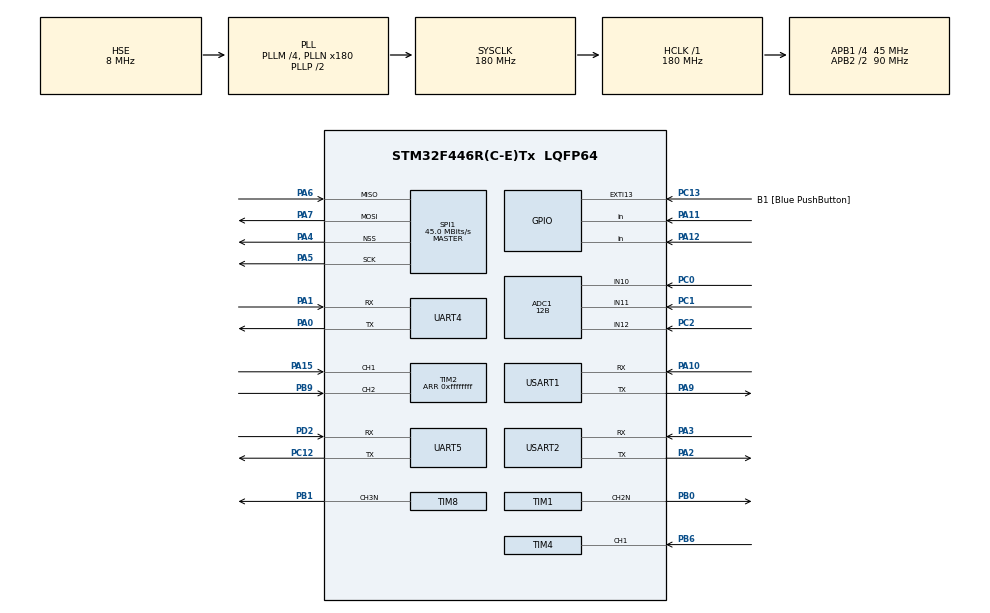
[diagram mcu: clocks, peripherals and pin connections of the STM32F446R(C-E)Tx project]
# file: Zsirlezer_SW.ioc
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ADC1.Channel-0\#ChannelRegularConversion=ADC_CHANNEL_10
ADC1.Channel-1\#ChannelRegularConversion=ADC_CHANNEL_11
ADC1.Channel-2\#ChannelRegularConversion=ADC_CHANNEL_12
ADC1.ClockPrescaler=ADC_CLOCK_SYNC_PCLK_DIV4
ADC1.ContinuousConvMode=DISABLE
ADC1.DMAContinuousRequests=ENABLE
ADC1.DataAlign=ADC_DATAALIGN_RIGHT
ADC1.DiscontinuousConvMode=DISABLE
ADC1.EOCSelection=ADC_EOC_SINGLE_CONV
ADC1.EnableAnalogWatchDog=false
ADC1.ExternalTrigConvEdge=ADC_EXTERNALTRIGCONVEDGE_NONE
ADC1.InjNumberOfConversion=0
ADC1.NbrOfConversion=3
ADC1.NbrOfConversionFlag=1
ADC1.Rank-0\#ChannelRegularConversion=1
ADC1.Rank-1\#ChannelRegularConversion=2
ADC1.Rank-2\#ChannelRegularConversion=3
ADC1.Resolution=ADC_RESOLUTION_12B
ADC1.SamplingTime-0\#ChannelRegularConversion=ADC_SAMPLETIME_15CYCLES
ADC1.SamplingTime-1\#ChannelRegularConversion=ADC_SAMPLETIME_15CYCLES
ADC1.SamplingTime-2\#ChannelRegularConversion=ADC_SAMPLETIME_15CYCLES
ADC1.ScanConvMode=ENABLE
ADC1.master=1
Dma.ADC1.0.Direction=DMA_PERIPH_TO_MEMORY
Dma.ADC1.0.FIFOMode=DMA_FIFOMODE_DISABLE
Dma.ADC1.0.Instance=DMA2_Stream0
Dma.ADC1.0.MemDataAlignment=DMA_MDATAALIGN_HALFWORD
Dma.ADC1.0.MemInc=DMA_MINC_ENABLE
Dma.ADC1.0.Mode=DMA_CIRCULAR
Dma.ADC1.0.PeriphDataAlignment=DMA_PDATAALIGN_HALFWORD
Dma.ADC1.0.PeriphInc=DMA_PINC_DISABLE
Dma.ADC1.0.Priority=DMA_PRIORITY_LOW
Dma.Request0=ADC1
Dma.Request1=USART1_RX
Dma.Request2=USART1_TX
Dma.USART1_RX.1.Direction=DMA_PERIPH_TO_MEMORY
Dma.USART1_RX.1.FIFOMode=DMA_FIFOMODE_DISABLE
Dma.USART1_RX.1.Instance=DMA2_Stream2
Dma.USART1_RX.1.MemDataAlignment=DMA_MDATAALIGN_BYTE
Dma.USART1_RX.1.MemInc=DMA_MINC_ENABLE
Dma.USART1_RX.1.Mode=DMA_CIRCULAR
Dma.USART1_RX.1.PeriphDataAlignment=DMA_PDATAALIGN_BYTE
Dma.USART1_RX.1.PeriphInc=DMA_PINC_DISABLE
Dma.USART1_RX.1.Priority=DMA_PRIORITY_HIGH
Dma.USART1_TX.2.Direction=DMA_MEMORY_TO_PERIPH
Dma.USART1_TX.2.FIFOMode=DMA_FIFOMODE_DISABLE
Dma.USART1_TX.2.Instance=DMA2_Stream7
Dma.USART1_TX.2.MemDataAlignment=DMA_MDATAALIGN_BYTE
Dma.USART1_TX.2.MemInc=DMA_MINC_ENABLE
Dma.USART1_TX.2.Mode=DMA_NORMAL
Dma.USART1_TX.2.PeriphDataAlignment=DMA_PDATAALIGN_BYTE
Dma.USART1_TX.2.PeriphInc=DMA_PINC_DISABLE
Dma.USART1_TX.2.Priority=DMA_PRIORITY_MEDIUM
Mcu.Family=STM32F4
Mcu.Name=STM32F446R(C-E)Tx
Mcu.Package=LQFP64
NVIC.DMA2_Stream0_IRQn=true\:0\:0\:false\:false\:true
NVIC.DMA2_Stream2_IRQn=true\:0\:0\:false\:false\:true
NVIC.DMA2_Stream7_IRQn=true\:0\:0\:false\:false\:true
NVIC.PriorityGroup=NVIC_PRIORITYGROUP_0
NVIC.TIM4_IRQn=true\:0\:2\:true\:false\:true
NVIC.TIM6_DAC_IRQn=true\:0\:2\:false\:false\:true
NVIC.TIM7_IRQn=true\:0\:2\:false\:false\:true
NVIC.UART4_IRQn=true\:0\:0\:false\:false\:true
NVIC.USART1_IRQn=true\:0\:0\:true\:false\:true
NVIC.USART2_IRQn=true\:0\:0\:false\:false\:true
PA0-WKUP.Mode=Asynchronous
PA0-WKUP.Signal=UART4_TX
PA1.Mode=Asynchronous
PA1.Signal=UART4_RX
PA10.Mode=Asynchronous
PA10.Signal=USART1_RX
PA11.Signal=GPIO_Input
PA12.Signal=GPIO_Input
PA13.GPIO_Label=TMS
PA13.Signal=SYS_JTMS-SWDIO
PA14.GPIO_Label=TCK
PA14.Signal=SYS_JTCK-SWCLK
PA15.Signal=S_TIM2_CH1_ETR
PA2.Mode=Asynchronous
PA2.Signal=USART2_TX
PA3.Mode=Asynchronous
PA3.Signal=USART2_RX
PA4.Mode=NSS_Signal_Hard_Output
PA4.Signal=SPI1_NSS
PA5.Mode=Full_Duplex_Master
PA5.Signal=SPI1_SCK
PA6.Mode=Full_Duplex_Master
PA6.Signal=SPI1_MISO
PA7.Mode=Full_Duplex_Master
PA7.Signal=SPI1_MOSI
PA9.Mode=Asynchronous
PA9.Signal=USART1_TX
PB0.GPIO_ModeDefaultPP=GPIO_MODE_AF_PP
PB0.Mode=PWM Generation2 CH2N
PB0.Signal=TIM1_CH2N
PB1.Mode=PWM Generation3 CH3N
PB1.Signal=TIM8_CH3N
PB3.GPIO_Label=SWO
PB3.Signal=SYS_JTDO-SWO
PB6.Signal=S_TIM4_CH1
PB9.Signal=S_TIM2_CH2
PC0.Signal=ADCx_IN10
PC1.Signal=ADCx_IN11
PC12.Mode=Asynchronous
PC12.Signal=UART5_TX
PC13.GPIO_Label=B1 [Blue PushButton]
PC13.GPIO_ModeDefaultEXTI=GPIO_MODE_EVT_RISING
PC13.Signal=GPXTI13
PC2.Signal=ADCx_IN12
PD2.Mode=Asynchronous
PD2.Signal=UART5_RX
PH0-OSC_IN.Mode=HSE-External-Oscillator
PH0-OSC_IN.Signal=RCC_OSC_IN
PH1-OSC_OUT.Mode=HSE-External-Oscillator
PH1-OSC_OUT.Signal=RCC_OSC_OUT
ProjectManager.HeapSize=0x200
ProjectManager.StackSize=0x400
ProjectManager.TargetToolchain=SW4STM32
RCC.AHBFreq_Value=180000000
RCC.APB1CLKDivider=RCC_HCLK_DIV4
RCC.APB1Freq_Value=45000000
RCC.APB1TimFreq_Value=90000000
RCC.APB2CLKDivider=RCC_HCLK_DIV2
RCC.APB2Freq_Value=90000000
RCC.APB2TimFreq_Value=180000000
RCC.CortexFreq_Value=180000000
RCC.FLatency-AdvancedSettings=FLASH_LATENCY_5
RCC.HCLKFreq_Value=180000000
RCC.HSE_VALUE=8000000
RCC.HSI_VALUE=16000000
RCC.LSE_VALUE=32768
RCC.PLLM=4
RCC.PLLN=180
RCC.PLLSourceVirtual=RCC_PLLSOURCE_HSE
RCC.SYSCLKFreq_VALUE=180000000
RCC.SYSCLKSource=RCC_SYSCLKSOURCE_PLLCLK
RCC.USBFreq_Value=180000000
RCC.VCOOutputFreq_Value=360000000
SH.ADCx_IN10.0=ADC1_IN10,IN10
SH.ADCx_IN11.0=ADC1_IN11,IN11
SH.ADCx_IN12.0=ADC1_IN12,IN12
SH.S_TIM2_CH1_ETR.0=TIM2_CH1,Encoder_Interface
SH.S_TIM2_CH2.0=TIM2_CH2,Encoder_Interface
SH.S_TIM4_CH1.0=TIM4_CH1,Input_Capture1_from_TI1
SPI1.CalculateBaudRate=45.0 MBits/s
SPI1.Mode=SPI_MODE_MASTER
SPI1.VirtualNSS=VM_NSSHARD
TIM1.Channel-PWM\ Generation2\ CH2N=TIM_CHANNEL_2
TIM1.Period=64614
TIM1.Prescaler=38
TIM1.Pulse-PWM\ Generation2\ CH2N=7497
TIM2.Period=0xffffffff
TIM4.ICPolarity_CH1=TIM_INPUTCHANNELPOLARITY_BOTHEDGE
TIM4.Period=64614
TIM4.Prescaler=38
TIM6.Period=65454
TIM6.Prescaler=65
TIM7.Period=9999
TIM7.Prescaler=89
TIM8.Channel-PWM\ Generation3\ CH3N=TIM_CHANNEL_3
TIM8.Period=64614
TIM8.Prescaler=38
TIM8.Pulse-PWM\ Generation3\ CH3N=6932
VP_TIM6_VS_ClockSourceINT.Mode=Enable_Timer
VP_TIM7_VS_ClockSourceINT.Mode=Enable_Timer
board=NUCLEO-F446RE

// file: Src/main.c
/**
  ******************************************************************************
  * File Name          : main.c
  * Description        : Main program body
  ******************************************************************************
  *
  * COPYRIGHT(c) 2017 STMicroelectronics
  *
  * Redistribution and use in source and binary forms, with or without modification,
  * are permitted provided that the following conditions are met:
  *   1. Redistributions of source code must retain the above copyright notice,
  *      this list of conditions and the following disclaimer.
  *   2. Redistributions in binary form must reproduce the above copyright notice,
  *      this list of conditions and the following disclaimer in the documentation
  *      and/or other materials provided with the distribution.
  *   3. Neither the name of STMicroelectronics nor the names of its contributors
  *      may be used to endorse or promote products derived from this software
  *      without specific prior written permission.
  *
  * THIS SOFTWARE IS PROVIDED BY THE COPYRIGHT HOLDERS AND CONTRIBUTORS "AS IS"
  * AND ANY EXPRESS OR IMPLIED WARRANTIES, INCLUDING, BUT NOT LIMITED TO, THE
  * IMPLIED WARRANTIES OF MERCHANTABILITY AND FITNESS FOR A PARTICULAR PURPOSE ARE
  * DISCLAIMED. IN NO EVENT SHALL THE COPYRIGHT HOLDER OR CONTRIBUTORS BE LIABLE
  * FOR ANY DIRECT, INDIRECT, INCIDENTAL, SPECIAL, EXEMPLARY, OR CONSEQUENTIAL
  * DAMAGES (INCLUDING, BUT NOT LIMITED TO, PROCUREMENT OF SUBSTITUTE GOODS OR
  * SERVICES; LOSS OF USE, DATA, OR PROFITS; OR BUSINESS INTERRUPTION) HOWEVER
  * CAUSED AND ON ANY THEORY OF LIABILITY, WHETHER IN CONTRACT, STRICT LIABILITY,
  * OR TORT (INCLUDING NEGLIGENCE OR OTHERWISE) ARISING IN ANY WAY OUT OF THE USE
  * OF THIS SOFTWARE, EVEN IF ADVISED OF THE POSSIBILITY OF SUCH DAMAGE.
  *
  ******************************************************************************
  */
#include "main.h"
#include "stm32f4xx_hal.h"
#include "adc.h"
#include "dma.h"
#include "spi.h"
#include "tim.h"
#include "usart.h"
#include "gpio.h"

/* USER CODE BEGIN Includes */
#include "stdbool.h"

//Defineok
//Vonalszam
#define NINCSVONAL 10
#define EGYVONAL 1
#define KETVONAL 2
#define HAROMVONAL 3
#define VONALHIBA 15
#define FULLVONAL 70

//UTVONANALVALASZTAS
#define JOBB 30
#define BAL 45
#define NORMAL_VONALKOVETES 50
#define MINDKET_OLDAL 60

//Vonalobjektumok
#define GYORSITO 5
#define LASSITO 6

#define DRONE 7
#define GYALOGOS 8
#define HORDO 9
#define KORFORGO 11
#define CEL 12
#define SIMA_VEZETOVONAL 13
#define STARTRA_VAR 22
#define LIBIKOKA_JOBBRA 16
#define LIBIKOKA_BALRA 17
#define TELEPHELY_JOBBRA 18
#define TELEPHELY_BALRA 19
#define PARKOLO_BALRA 20
#define PARKOLO_JOBBRA 21

/* USER CODE END Includes */

/* USER CODE BEGIN PV */
/* Private variables ---------------------------------------------------------*/

float atan_lut[5400] = {
	 2320.5616,
	 2320.0878, 2319.6137, 2319.1394, 2318.6649, 2318.1902, 2317.7153, 2317.2401, 2316.7648, 2316.2892, 2315.8135,
	 2315.3375, 2314.8613, 2314.3849, 2313.9083, 2313.4314, 2312.9544, 2312.4771, 2311.9997, 2311.522, 2311.0441,
	 2310.566, 2310.0876, 2309.6091, 2309.1303, 2308.6514, 2308.1722, 2307.6928, 2307.2132, 2306.7334, 2306.2533,
	 2305.7731, 2305.2926, 2304.8119, 2304.331, 2303.8499, 2303.3686, 2302.8871, 2302.4053, 2301.9233, 2301.4411,
	 2300.9587, 2300.4761, 2299.9933, 2299.5102, 2299.027, 2298.5435, 2298.0598, 2297.5759, 2297.0917, 2296.6074,
	 2296.1228, 2295.638, 2295.153, 2294.6678, 2294.1824, 2293.6967, 2293.2109, 2292.7248, 2292.2385, 2291.7519,
	 2291.2652, 2290.7782, 2290.2911, 2289.8037, 2289.3161, 2288.8282, 2288.3402, 2287.8519, 2287.3634, 2286.8747,
	 2286.3858, 2285.8967, 2285.4073, 2284.9177, 2284.4279, 2283.9379, 2283.4476, 2282.9572, 2282.4665, 2281.9756,
	 2281.4845, 2280.9931, 2280.5016, 2280.0098, 2279.5178, 2279.0256, 2278.5331, 2278.0404, 2277.5476, 2277.0544,
	 2276.5611, 2276.0676, 2275.5738, 2275.0798, 2274.5856, 2274.0911, 2273.5965, 2273.1016, 2272.6065, 2272.1112,
	 2271.6156, 2271.1199, 2270.6239, 2270.1276, 2269.6312, 2269.1345, 2268.6377, 2268.1405, 2267.6432, 2267.1457,
	 2266.6479, 2266.1499, 2265.6517, 2265.1532, 2264.6545, 2264.1556, 2263.6565, 2263.1572, 2262.6576, 2262.1578,
	 2261.6578, 2261.1575, 2260.657, 2260.1563, 2259.6554, 2259.1543, 2258.6529, 2258.1513, 2257.6495, 2257.1474,
	 2256.6452, 2256.1427, 2255.6399, 2255.137, 2254.6338, 2254.1304, 2253.6268, 2253.1229, 2252.6188, 2252.1145,
	 2251.61, 2251.1052, 2250.6002, 2250.095, 2249.5895, 2249.0839, 2248.5779, 2248.0718, 2247.5655, 2247.0589,
	 2246.552, 2246.045, 2245.5377, 2245.0302, 2244.5225, 2244.0145, 2243.5063, 2242.9979, 2242.4893, 2241.9804,
	 2241.4713, 2240.962, 2240.4524, 2239.9426, 2239.4326, 2238.9223, 2238.4118, 2237.9011, 2237.3902, 2236.879,
	 2236.3676, 2235.856, 2235.3441, 2234.832, 2234.3197, 2233.8071, 2233.2943, 2232.7813, 2232.2681, 2231.7546,
	 2231.2409, 2230.7269, 2230.2127, 2229.6983, 2229.1837, 2228.6688, 2228.1537, 2227.6383, 2227.1228, 2226.607,
	 2226.0909, 2225.5746, 2225.0581, 2224.5414, 2224.0244, 2223.5072, 2222.9898, 2222.4721, 2221.9542, 2221.4361,
	 2220.9177, 2220.3991, 2219.8802, 2219.3612, 2218.8418, 2218.3223, 2217.8025, 2217.2825, 2216.7622, 2216.2418,
	 2215.721, 2215.2001, 2214.6789, 2214.1575, 2213.6358, 2213.1139, 2212.5918, 2212.0694, 2211.5468, 2211.0239,
	 2210.5009, 2209.9775, 2209.454, 2208.9302, 2208.4062, 2207.8819, 2207.3574, 2206.8327, 2206.3077, 2205.7825,
	 2205.257, 2204.7313, 2204.2054, 2203.6792, 2203.1528, 2202.6262, 2202.0993, 2201.5722, 2201.0448, 2200.5172,
	 2199.9894, 2199.4613, 2198.933, 2198.4045, 2197.8757, 2197.3467, 2196.8174, 2196.2879, 2195.7581, 2195.2281,
	 2194.6979, 2194.1675, 2193.6367, 2193.1058, 2192.5746, 2192.0432, 2191.5115, 2190.9796, 2190.4474, 2189.9151,
	 2189.3824, 2188.8495, 2188.3164, 2187.7831, 2187.2495, 2186.7156, 2186.1815, 2185.6472, 2185.1126, 2184.5778,
	 2184.0428, 2183.5075, 2182.972, 2182.4362, 2181.9002, 2181.3639, 2180.8274, 2180.2906, 2179.7536, 2179.2164,
	 2178.6789, 2178.1412, 2177.6032, 2177.065, 2176.5265, 2175.9878, 2175.4489, 2174.9097, 2174.3703, 2173.8306,
	 2173.2907, 2172.7505, 2172.2101, 2171.6694, 2171.1285, 2170.5874, 2170.046, 2169.5043, 2168.9624, 2168.4203,
	 2167.8779, 2167.3353, 2166.7924, 2166.2493, 2165.706, 2165.1623, 2164.6185, 2164.0744, 2163.53, 2162.9854,
	 2162.4406, 2161.8955, 2161.3502, 2160.8046, 2160.2587, 2159.7127, 2159.1663, 2158.6197, 2158.0729, 2157.5258,
	 2156.9785, 2156.4309, 2155.8831, 2155.3351, 2154.7867, 2154.2382, 2153.6894, 2153.1403, 2152.591, 2152.0414,
	 2151.4916, 2150.9415, 2150.3912, 2149.8407, 2149.2898, 2148.7388, 2148.1875, 2147.6359, 2147.0841, 2146.532,
	 2145.9797, 2145.4271, 2144.8743, 2144.3212, 2143.7679, 2143.2144, 2142.6605, 2142.1065, 2141.5521, 2140.9976,
	 2140.4427, 2139.8876, 2139.3323, 2138.7767, 2138.2209, 2137.6648, 2137.1084, 2136.5518, 2135.995, 2135.4379,
	 2134.8805, 2134.3229, 2133.765, 2133.2069, 2132.6486, 2132.0899, 2131.531, 2130.9719, 2130.4125, 2129.8529,
	 2129.293, 2128.7328, 2128.1724, 2127.6118, 2127.0508, 2126.4897, 2125.9282, 2125.3666, 2124.8046, 2124.2424,
	 2123.68, 2123.1173, 2122.5543, 2121.9911, 2121.4276, 2120.8639, 2120.2999, 2119.7357, 2119.1712, 2118.6064,
	 2118.0414, 2117.4761, 2116.9106, 2116.3448, 2115.7788, 2115.2125, 2114.6459, 2114.0791, 2113.512, 2112.9447,
	 2112.3771, 2111.8093, 2111.2412, 2110.6728, 2110.1042, 2109.5353, 2108.9662, 2108.3968, 2107.8271, 2107.2572,
	 2106.687, 2106.1166, 2105.5459, 2104.9749, 2104.4037, 2103.8322, 2103.2605, 2102.6885, 2102.1163, 2101.5437,
	 2100.971, 2100.3979, 2099.8246, 2099.2511, 2098.6773, 2098.1032, 2097.5288, 2096.9542, 2096.3794, 2095.8042,
	 2095.2288, 2094.6532, 2094.0773, 2093.5011, 2092.9247, 2092.348, 2091.771, 2091.1938, 2090.6163, 2090.0385,
	 2089.4605, 2088.8822, 2088.3037, 2087.7249, 2087.1458, 2086.5665, 2085.9869, 2085.407, 2084.8269, 2084.2465,
	 2083.6659, 2083.085, 2082.5038, 2081.9223, 2081.3406, 2080.7587, 2080.1764, 2079.5939, 2079.0111, 2078.4281,
	 2077.8448, 2077.2612, 2076.6774, 2076.0933, 2075.5089, 2074.9243, 2074.3394, 2073.7543, 2073.1688, 2072.5831,
	 2071.9972, 2071.4109, 2070.8244, 2070.2377, 2069.6506, 2069.0633, 2068.4758, 2067.8879, 2067.2998, 2066.7115,
	 2066.1228, 2065.5339, 2064.9448, 2064.3553, 2063.7656, 2063.1756, 2062.5854, 2061.9949, 2061.4041, 2060.813,
	 2060.2217, 2059.6301, 2059.0382, 2058.4461, 2057.8537, 2057.261, 2056.6681, 2056.0749, 2055.4814, 2054.8876,
	 2054.2936, 2053.6993, 2053.1048, 2052.5099, 2051.9148, 2051.3194, 2050.7238, 2050.1279, 2049.5317, 2048.9352,
	 2048.3385, 2047.7415, 2047.1442, 2046.5467, 2045.9488, 2045.3507, 2044.7524, 2044.1537, 2043.5548, 2042.9556,
	 2042.3562, 2041.7564, 2041.1564, 2040.5562, 2039.9556, 2039.3548, 2038.7537, 2038.1523, 2037.5507, 2036.9488,
	 2036.3466, 2035.7441, 2035.1414, 2034.5383, 2033.935, 2033.3315, 2032.7276, 2032.1235, 2031.5191, 2030.9145,
	 2030.3095, 2029.7043, 2029.0988, 2028.493, 2027.887, 2027.2807, 2026.6741, 2026.0672, 2025.4601, 2024.8526,
	 2024.2449, 2023.6369, 2023.0287, 2022.4202, 2021.8113, 2021.2023, 2020.5929, 2019.9833, 2019.3733, 2018.7631,
	 2018.1527, 2017.5419, 2016.9309, 2016.3196, 2015.708, 2015.0961, 2014.484, 2013.8715, 2013.2588, 2012.6459,
	 2012.0326, 2011.4191, 2010.8052, 2010.1911, 2009.5768, 2008.9621, 2008.3472, 2007.7319, 2007.1165, 2006.5007,
	 2005.8846, 2005.2683, 2004.6517, 2004.0348, 2003.4176, 2002.8001, 2002.1824, 2001.5643, 2000.946, 2000.3275,
	 1999.7086, 1999.0894, 1998.47, 1997.8503, 1997.2303, 1996.61, 1995.9895, 1995.3686, 1994.7475, 1994.1261,
	 1993.5044, 1992.8824, 1992.2602, 1991.6376, 1991.0148, 1990.3917, 1989.7683, 1989.1446, 1988.5207, 1987.8964,
	 1987.2719, 1986.6471, 1986.022, 1985.3966, 1984.771, 1984.145, 1983.5188, 1982.8923, 1982.2655, 1981.6384,
	 1981.011, 1980.3834, 1979.7554, 1979.1272, 1978.4987, 1977.8699, 1977.2408, 1976.6114, 1975.9818, 1975.3518,
	 1974.7216, 1974.0911, 1973.4603, 1972.8292, 1972.1978, 1971.5661, 1970.9342, 1970.302, 1969.6694, 1969.0366,
	 1968.4035, 1967.7701, 1967.1364, 1966.5025, 1965.8682, 1965.2337, 1964.5989, 1963.9637, 1963.3283, 1962.6926,
	 1962.0567, 1961.4204, 1960.7838, 1960.147, 1959.5098, 1958.8724, 1958.2347, 1957.5967, 1956.9584, 1956.3198,
	 1955.6809, 1955.0417, 1954.4023, 1953.7625, 1953.1225, 1952.4821, 1951.8415, 1951.2006, 1950.5594, 1949.9179,
	 1949.2761, 1948.634, 1947.9917, 1947.349, 1946.706, 1946.0628, 1945.4193, 1944.7754, 1944.1313, 1943.4869,
	 1942.8422, 1942.1972, 1941.5519, 1940.9063, 1940.2604, 1939.6143, 1938.9678, 1938.321, 1937.674, 1937.0266,
	 1936.379, 1935.7311, 1935.0828, 1934.4343, 1933.7855, 1933.1364, 1932.487, 1931.8373, 1931.1873, 1930.537,
	 1929.8864, 1929.2356, 1928.5844, 1927.9329, 1927.2812, 1926.6291, 1925.9767, 1925.3241, 1924.6712, 1924.0179,
	 1923.3644, 1922.7105, 1922.0564, 1921.402, 1920.7473, 1920.0922, 1919.4369, 1918.7813, 1918.1254, 1917.4692,
	 1916.8127, 1916.1559, 1915.4988, 1914.8414, 1914.1837, 1913.5257, 1912.8674, 1912.2088, 1911.5499, 1910.8907,
	 1910.2312, 1909.5715, 1908.9114, 1908.251, 1907.5903, 1906.9293, 1906.2681, 1905.6065, 1904.9446, 1904.2824,
	 1903.6199, 1902.9572, 1902.2941, 1901.6307, 1900.967, 1900.3031, 1899.6388, 1898.9742, 1898.3093, 1897.6442,
	 1896.9787, 1896.3129, 1895.6468, 1894.9804, 1894.3137, 1893.6468, 1892.9795, 1892.3119, 1891.644, 1890.9758,
	 1890.3073, 1889.6385, 1888.9694, 1888.3, 1887.6303, 1886.9603, 1886.29, 1885.6194, 1884.9485, 1884.2772,
	 1883.6057, 1882.9339, 1882.2618, 1881.5893, 1880.9166, 1880.2435, 1879.5702, 1878.8966, 1878.2226, 1877.5483,
	 1876.8738, 1876.1989, 1875.5238, 1874.8483, 1874.1725, 1873.4964, 1872.82, 1872.1433, 1871.4663, 1870.789,
	 1870.1114, 1869.4335, 1868.7553, 1868.0768, 1867.3979, 1866.7188, 1866.0393, 1865.3596, 1864.6795, 1863.9992,
	 1863.3185, 1862.6375, 1861.9562, 1861.2746, 1860.5927, 1859.9105, 1859.228, 1858.5452, 1857.8621, 1857.1786,
	 1856.4949, 1855.8108, 1855.1265, 1854.4418, 1853.7568, 1853.0715, 1852.3859, 1851.7, 1851.0138, 1850.3273,
	 1849.6405, 1848.9533, 1848.2659, 1847.5781, 1846.8901, 1846.2017, 1845.513, 1844.824, 1844.1347, 1843.4451,
	 1842.7551, 1842.0649, 1841.3744, 1840.6835, 1839.9923, 1839.3009, 1838.6091, 1837.917, 1837.2246, 1836.5318,
	 1835.8388, 1835.1455, 1834.4518, 1833.7578, 1833.0636, 1832.369, 1831.6741, 1830.9789, 1830.2833, 1829.5875,
	 1828.8913, 1828.1949, 1827.4981, 1826.801, 1826.1036, 1825.4059, 1824.7079, 1824.0095, 1823.3109, 1822.6119,
	 1821.9126, 1821.213, 1820.5131, 1819.8129, 1819.1124, 1818.4115, 1817.7103, 1817.0089, 1816.3071, 1815.605,
	 1814.9025, 1814.1998, 1813.4968, 1812.7934, 1812.0897, 1811.3857, 1810.6814, 1809.9768, 1809.2718, 1808.5666,
	 1807.861, 1807.1551, 1806.4489, 1805.7424, 1805.0355, 1804.3284, 1803.6209, 1802.9131, 1802.205, 1801.4966,
	 1800.7879, 1800.0788, 1799.3695, 1798.6598, 1797.9498, 1797.2394, 1796.5288, 1795.8179, 1795.1066, 1794.395,
	 1793.6831, 1792.9708, 1792.2583, 1791.5454, 1790.8323, 1790.1188, 1789.4049, 1788.6908, 1787.9763, 1787.2616,
	 1786.5465, 1785.8311, 1785.1153, 1784.3993, 1783.6829, 1782.9662, 1782.2492, 1781.5319, 1780.8142, 1780.0963,
	 1779.378, 1778.6594, 1777.9404, 1777.2212, 1776.5016, 1775.7817, 1775.0615, 1774.341, 1773.6201, 1772.899,
	 1772.1775, 1771.4557, 1770.7335, 1770.0111, 1769.2883, 1768.5652, 1767.8418, 1767.118, 1766.394, 1765.6696,
	 1764.9449, 1764.2198, 1763.4945, 1762.7688, 1762.0428, 1761.3165, 1760.5898, 1759.8629, 1759.1356, 1758.408,
	 1757.68, 1756.9518, 1756.2232, 1755.4943, 1754.7651, 1754.0355, 1753.3056, 1752.5754, 1751.8449, 1751.1141,
	 1750.3829, 1749.6514, 1748.9196, 1748.1874, 1747.455, 1746.7222, 1745.9891, 1745.2556, 1744.5218, 1743.7878,
	 1743.0533, 1742.3186, 1741.5835, 1740.8481, 1740.1124, 1739.3764, 1738.64, 1737.9033, 1737.1663, 1736.4289,
	 1735.6913, 1734.9533, 1734.2149, 1733.4763, 1732.7373, 1731.998, 1731.2584, 1730.5184, 1729.7781, 1729.0375,
	 1728.2966, 1727.5553, 1726.8137, 1726.0718, 1725.3295, 1724.5869, 1723.844, 1723.1008, 1722.3572, 1721.6134,
	 1720.8691, 1720.1246, 1719.3797, 1718.6345, 1717.889, 1717.1431, 1716.397, 1715.6504, 1714.9036, 1714.1564,
	 1713.4089, 1712.6611, 1711.9129, 1711.1644, 1710.4156, 1709.6665, 1708.917, 1708.1672, 1707.417, 1706.6666,
	 1705.9158, 1705.1647, 1704.4132, 1703.6614, 1702.9093, 1702.1568, 1701.4041, 1700.651, 1699.8975, 1699.1438,
	 1698.3896, 1697.6352, 1696.8805, 1696.1254, 1695.3699, 1694.6142, 1693.8581, 1693.1017, 1692.3449, 1691.5878,
	 1690.8304, 1690.0727, 1689.3146, 1688.5562, 1687.7974, 1687.0384, 1686.279, 1685.5192, 1684.7591, 1683.9987,
	 1683.238, 1682.4769, 1681.7155, 1680.9538, 1680.1917, 1679.4293, 1678.6666, 1677.9035, 1677.1401, 1676.3764,
	 1675.6123, 1674.8479, 1674.0832, 1673.3181, 1672.5527, 1671.787, 1671.0209, 1670.2545, 1669.4877, 1668.7207,
	 1667.9532, 1667.1855, 1666.4174, 1665.649, 1664.8803, 1664.1112, 1663.3418, 1662.572, 1661.8019, 1661.0315,
	 1660.2607, 1659.4896, 1658.7182, 1657.9464, 1657.1743, 1656.4019, 1655.6291, 1654.856, 1654.0826, 1653.3088,
	 1652.5347, 1651.7602, 1650.9854, 1650.2103, 1649.4349, 1648.6591, 1647.8829, 1647.1065, 1646.3296, 1645.5525,
	 1644.775, 1643.9972, 1643.219, 1642.4405, 1641.6617, 1640.8825, 1640.103, 1639.3232, 1638.543, 1637.7625,
	 1636.9816, 1636.2004, 1635.4189, 1634.637, 1633.8548, 1633.0723, 1632.2894, 1631.5062, 1630.7226, 1629.9387,
	 1629.1545, 1628.3699, 1627.585, 1626.7997, 1626.0141, 1625.2282, 1624.4419, 1623.6553, 1622.8684, 1622.0811,
	 1621.2935, 1620.5055, 1619.7172, 1618.9285, 1618.1396, 1617.3502, 1616.5606, 1615.7706, 1614.9802, 1614.1895,
	 1613.3985, 1612.6071, 1611.8154, 1611.0234, 1610.231, 1609.4383, 1608.6452, 1607.8518, 1607.058, 1606.264,
	 1605.4695, 1604.6748, 1603.8796, 1603.0842, 1602.2884, 1601.4923, 1600.6958, 1599.899, 1599.1018, 1598.3043,
	 1597.5065, 1596.7083, 1595.9098, 1595.1109, 1594.3117, 1593.5121, 1592.7122, 1591.912, 1591.1114, 1590.3105,
	 1589.5092, 1588.7076, 1587.9057, 1587.1034, 1586.3008, 1585.4978, 1584.6945, 1583.8908, 1583.0868, 1582.2825,
	 1581.4778, 1580.6728, 1579.8674, 1579.0617, 1578.2556, 1577.4492, 1576.6425, 1575.8354, 1575.0279, 1574.2202,
	 1573.412, 1572.6036, 1571.7948, 1570.9856, 1570.1761, 1569.3663, 1568.5561, 1567.7456, 1566.9347, 1566.1235,
	 1565.3119, 1564.5, 1563.6878, 1562.8752, 1562.0622, 1561.249, 1560.4353, 1559.6214, 1558.807, 1557.9924,
	 1557.1774, 1556.362, 1555.5463, 1554.7303, 1553.9139, 1553.0972, 1552.2801, 1551.4627, 1550.6449, 1549.8268,
	 1549.0084, 1548.1896, 1547.3704, 1546.5509, 1545.7311, 1544.9109, 1544.0904, 1543.2695, 1542.4483, 1541.6267,
	 1540.8048, 1539.9825, 1539.1599, 1538.337, 1537.5137, 1536.69, 1535.866, 1535.0417, 1534.217, 1533.392,
	 1532.5666, 1531.7409, 1530.9148, 1530.0884, 1529.2616, 1528.4345, 1527.6071, 1526.7793, 1525.9511, 1525.1226,
	 1524.2938, 1523.4646, 1522.635, 1521.8052, 1520.9749, 1520.1443, 1519.3134, 1518.4821, 1517.6505, 1516.8186,
	 1515.9862, 1515.1536, 1514.3206, 1513.4872, 1512.6535, 1511.8194, 1510.985, 1510.1503, 1509.3152, 1508.4797,
	 1507.6439, 1506.8078, 1505.9713, 1505.1345, 1504.2973, 1503.4597, 1502.6218, 1501.7836, 1500.945, 1500.1061,
	 1499.2668, 1498.4272, 1497.5872, 1496.7469, 1495.9062, 1495.0652, 1494.2238, 1493.3821, 1492.54, 1491.6976,
	 1490.8549, 1490.0117, 1489.1683, 1488.3245, 1487.4803, 1486.6358, 1485.7909, 1484.9457, 1484.1002, 1483.2543,
	 1482.408, 1481.5614, 1480.7144, 1479.8671, 1479.0195, 1478.1715, 1477.3231, 1476.4744, 1475.6254, 1474.776,
	 1473.9262, 1473.0761, 1472.2256, 1471.3748, 1470.5237, 1469.6722, 1468.8203, 1467.9681, 1467.1156, 1466.2627,
	 1465.4094, 1464.5558, 1463.7019, 1462.8476, 1461.9929, 1461.1379, 1460.2826, 1459.4269, 1458.5708, 1457.7144,
	 1456.8577, 1456.0006, 1455.1431, 1454.2853, 1453.4271, 1452.5686, 1451.7098, 1450.8506, 1449.991, 1449.1311,
	 1448.2708, 1447.4102, 1446.5493, 1445.688, 1444.8263, 1443.9643, 1443.1019, 1442.2392, 1441.3761, 1440.5127,
	 1439.649, 1438.7848, 1437.9204, 1437.0556, 1436.1904, 1435.3249, 1434.459, 1433.5928, 1432.7262, 1431.8593,
	 1430.992, 1430.1244, 1429.2564, 1428.388, 1427.5194, 1426.6503, 1425.7809, 1424.9112, 1424.0411, 1423.1707,
	 1422.2999, 1421.4288, 1420.5573, 1419.6854, 1418.8132, 1417.9407, 1417.0678, 1416.1945, 1415.3209, 1414.447,
	 1413.5727, 1412.698, 1411.823, 1410.9476, 1410.0719, 1409.1959, 1408.3194, 1407.4427, 1406.5656, 1405.6881,
	 1404.8103, 1403.9321, 1403.0536, 1402.1747, 1401.2955, 1400.4159, 1399.536, 1398.6557, 1397.775, 1396.894,
	 1396.0127, 1395.131, 1394.249, 1393.3666, 1392.4838, 1391.6007, 1390.7173, 1389.8335, 1388.9493, 1388.0648,
	 1387.18, 1386.2948, 1385.4092, 1384.5233, 1383.637, 1382.7504, 1381.8634, 1380.9761, 1380.0884, 1379.2004,
	 1378.312, 1377.4233, 1376.5342, 1375.6448, 1374.755, 1373.8649, 1372.9744, 1372.0835, 1371.1923, 1370.3008,
	 1369.4089, 1368.5166, 1367.624, 1366.7311, 1365.8378, 1364.9441, 1364.0501, 1363.1558, 1362.261, 1361.366,
	 1360.4706, 1359.5748, 1358.6787, 1357.7822, 1356.8854, 1355.9882, 1355.0907, 1354.1928, 1353.2946, 1352.396,
	 1351.497, 1350.5978, 1349.6981, 1348.7981, 1347.8978, 1346.9971, 1346.096, 1345.1946, 1344.2929, 1343.3908,
	 1342.4883, 1341.5855, 1340.6824, 1339.7788, 1338.875, 1337.9708, 1337.0662, 1336.1613, 1335.256, 1334.3504,
	 1333.4444, 1332.5381, 1331.6314, 1330.7244, 1329.817, 1328.9093, 1328.0012, 1327.0927, 1326.184, 1325.2748,
	 1324.3653, 1323.4555, 1322.5453, 1321.6348, 1320.7239, 1319.8126, 1318.901, 1317.9891, 1317.0768, 1316.1641,
	 1315.2511, 1314.3377, 1313.424, 1312.51, 1311.5956, 1310.6808, 1309.7657, 1308.8502, 1307.9344, 1307.0182,
	 1306.1017, 1305.1848, 1304.2676, 1303.3501, 1302.4321, 1301.5139, 1300.5952, 1299.6763, 1298.7569, 1297.8373,
	 1296.9172, 1295.9968, 1295.0761, 1294.155, 1293.2336, 1292.3118, 1291.3897, 1290.4672, 1289.5444, 1288.6212,
	 1287.6976, 1286.7737, 1285.8495, 1284.9249, 1284, 1283.0747, 1282.149, 1281.2231, 1280.2967, 1279.37,
	 1278.443, 1277.5156, 1276.5878, 1275.6598, 1274.7313, 1273.8025, 1272.8734, 1271.9439, 1271.014, 1270.0838,
	 1269.1533, 1268.2224, 1267.2912, 1266.3596, 1265.4276, 1264.4953, 1263.5627, 1262.6297, 1261.6964, 1260.7627,
	 1259.8286, 1258.8942, 1257.9595, 1257.0244, 1256.089, 1255.1532, 1254.217, 1253.2806, 1252.3437, 1251.4065,
	 1250.469, 1249.5311, 1248.5929, 1247.6543, 1246.7154, 1245.7761, 1244.8365, 1243.8965, 1242.9562, 1242.0155,
	 1241.0745, 1240.1331, 1239.1914, 1238.2493, 1237.3069, 1236.3641, 1235.421, 1234.4775, 1233.5337, 1232.5896,
	 1231.6451, 1230.7002, 1229.755, 1228.8095, 1227.8636, 1226.9173, 1225.9707, 1225.0238, 1224.0765, 1223.1288,
	 1222.1809, 1221.2325, 1220.2838, 1219.3348, 1218.3854, 1217.4357, 1216.4857, 1215.5352, 1214.5845, 1213.6334,
	 1212.6819, 1211.7301, 1210.778, 1209.8255, 1208.8726, 1207.9194, 1206.9659, 1206.012, 1205.0578, 1204.1032,
	 1203.1483, 1202.193, 1201.2374, 1200.2814, 1199.3251, 1198.3685, 1197.4115, 1196.4541, 1195.4964, 1194.5384,
	 1193.58, 1192.6213, 1191.6622, 1190.7028, 1189.743, 1188.7829, 1187.8224, 1186.8616, 1185.9005, 1184.939,
	 1183.9772, 1183.015, 1182.0525, 1181.0896, 1180.1264, 1179.1628, 1178.1989, 1177.2347, 1176.2701, 1175.3051,
	 1174.3399, 1173.3742, 1172.4083, 1171.442, 1170.4753, 1169.5083, 1168.541, 1167.5733, 1166.6052, 1165.6369,
	 1164.6682, 1163.6991, 1162.7297, 1161.7599, 1160.7899, 1159.8194, 1158.8486, 1157.8775, 1156.9061, 1155.9343,
	 1154.9621, 1153.9896, 1153.0168, 1152.0436, 1151.0701, 1150.0963, 1149.1221, 1148.1475, 1147.1726, 1146.1974,
	 1145.2218, 1144.2459, 1143.2697, 1142.2931, 1141.3162, 1140.3389, 1139.3613, 1138.3833, 1137.405, 1136.4264,
	 1135.4474, 1134.4681, 1133.4885, 1132.5085, 1131.5281, 1130.5474, 1129.5664, 1128.5851, 1127.6034, 1126.6213,
	 1125.639, 1124.6562, 1123.6732, 1122.6898, 1121.7061, 1120.722, 1119.7376, 1118.7528, 1117.7677, 1116.7823,
	 1115.7965, 1114.8104, 1113.824, 1112.8372, 1111.8501, 1110.8626, 1109.8748, 1108.8867, 1107.8982, 1106.9094,
	 1105.9203, 1104.9308, 1103.941, 1102.9508, 1101.9603, 1100.9695, 1099.9783, 1098.9868, 1097.9949, 1097.0028,
	 1096.0103, 1095.0174, 1094.0242, 1093.0307, 1092.0368, 1091.0426, 1090.0481, 1089.0532, 1088.058, 1087.0625,
	 1086.0666, 1085.0704, 1084.0739, 1083.077, 1082.0798, 1081.0822, 1080.0843, 1079.0861, 1078.0876, 1077.0887,
	 1076.0895, 1075.0899, 1074.09, 1073.0898, 1072.0893, 1071.0884, 1070.0871, 1069.0856, 1068.0837, 1067.0815,
	 1066.0789, 1065.0761, 1064.0728, 1063.0693, 1062.0654, 1061.0612, 1060.0566, 1059.0518, 1058.0466, 1057.041,
	 1056.0352, 1055.0289, 1054.0224, 1053.0155, 1052.0084, 1051.0008, 1049.993, 1048.9848, 1047.9763, 1046.9674,
	 1045.9582, 1044.9487, 1043.9389, 1042.9287, 1041.9182, 1040.9074, 1039.8962, 1038.8848, 1037.8729, 1036.8608,
	 1035.8483, 1034.8355, 1033.8224, 1032.809, 1031.7952, 1030.7811, 1029.7666, 1028.7519, 1027.7368, 1026.7213,
	 1025.7056, 1024.6895, 1023.6731, 1022.6564, 1021.6393, 1020.6219, 1019.6042, 1018.5862, 1017.5678, 1016.5491,
	 1015.5301, 1014.5108, 1013.4911, 1012.4711, 1011.4508, 1010.4302, 1009.4092, 1008.3879, 1007.3663, 1006.3444,
	 1005.3221, 1004.2996, 1003.2766, 1002.2534, 1001.2299, 1000.206, 999.1818, 998.1573, 997.1324, 996.1072,
	 995.0818, 994.0559, 993.0298, 992.0033, 990.9766, 989.9495, 988.922, 987.8943, 986.8662, 985.8378,
	 984.8091, 983.7801, 982.7508, 981.7211, 980.6911, 979.6608, 978.6302, 977.5992, 976.5679, 975.5364,
	 974.5044, 973.4722, 972.4397, 971.4068, 970.3736, 969.3401, 968.3063, 967.2722, 966.2377, 965.203,
	 964.1679, 963.1325, 962.0967, 961.0607, 960.0244, 958.9877, 957.9507, 956.9134, 955.8758, 954.8378,
	 953.7996, 952.761, 951.7221, 950.6829, 949.6434, 948.6036, 947.5635, 946.523, 945.4822, 944.4412,
	 943.3998, 942.358, 941.316, 940.2737, 939.231, 938.1881, 937.1448, 936.1012, 935.0573, 934.0131,
	 932.9686, 931.9237, 930.8786, 929.8331, 928.7874, 927.7413, 926.6949, 925.6482, 924.6012, 923.5539,
	 922.5063, 921.4583, 920.4101, 919.3615, 918.3126, 917.2635, 916.214, 915.1642, 914.1141, 913.0637,
	 912.013, 910.9619, 909.9106, 908.859, 907.807, 906.7548, 905.7022, 904.6494, 903.5962, 902.5427,
	 901.4889, 900.4348, 899.3805, 898.3258, 897.2708, 896.2154, 895.1598, 894.1039, 893.0477, 891.9912,
	 890.9343, 889.8772, 888.8198, 887.762, 886.704, 885.6457, 884.587, 883.5281, 882.4688, 881.4093,
	 880.3494, 879.2893, 878.2288, 877.1681, 876.107, 875.0457, 873.984, 872.922, 871.8598, 870.7972,
	 869.7344, 868.6712, 867.6078, 866.544, 865.48, 864.4156, 863.351, 862.2861, 861.2208, 860.1553,
	 859.0894, 858.0233, 856.9569, 855.8902, 854.8232, 853.7558, 852.6882, 851.6203, 850.5521, 849.4836,
	 848.4148, 847.3458, 846.2764, 845.2067, 844.1367, 843.0665, 841.9959, 840.9251, 839.854, 838.7825,
	 837.7108, 836.6388, 835.5665, 834.4939, 833.421, 832.3478, 831.2744, 830.2006, 829.1266, 828.0522,
	 826.9776, 825.9027, 824.8275, 823.752, 822.6762, 821.6001, 820.5237, 819.4471, 818.3701, 817.2929,
	 816.2154, 815.1376, 814.0595, 812.9811, 811.9025, 810.8235, 809.7443, 808.6648, 807.585, 806.5049,
	 805.4245, 804.3439, 803.2629, 802.1817, 801.1002, 800.0184, 798.9363, 797.854, 796.7713, 795.6884,
	 794.6052, 793.5217, 792.4379, 791.3539, 790.2696, 789.185, 788.1001, 787.0149, 785.9294, 784.8437,
	 783.7577, 782.6714, 781.5848, 780.498, 779.4109, 778.3234, 777.2358, 776.1478, 775.0596, 773.971,
	 772.8823, 771.7932, 770.7038, 769.6142, 768.5243, 767.4342, 766.3437, 765.253, 764.162, 763.0707,
	 761.9792, 760.8874, 759.7953, 758.7029, 757.6103, 756.5173, 755.4242, 754.3307, 753.237, 752.143,
	 751.0487, 749.9542, 748.8594, 747.7643, 746.6689, 745.5733, 744.4774, 743.3813, 742.2848, 741.1881,
	 740.0912, 738.9939, 737.8964, 736.7987, 735.7006, 734.6023, 733.5037, 732.4049, 731.3058, 730.2064,
	 729.1068, 728.0069, 726.9067, 725.8063, 724.7056, 723.6047, 722.5034, 721.4019, 720.3002, 719.1982,
	 718.0959, 716.9934, 715.8906, 714.7875, 713.6842, 712.5806, 711.4768, 710.3727, 709.2683, 708.1637,
	 707.0588, 705.9537, 704.8483, 703.7426, 702.6367, 701.5305, 700.4241, 699.3174, 698.2105, 697.1032,
	 695.9958, 694.8881, 693.7801, 692.6719, 691.5634, 690.4547, 689.3457, 688.2364, 687.1269, 686.0172,
	 684.9071, 683.7969, 682.6864, 681.5756, 680.4646, 679.3533, 678.2418, 677.13, 676.018, 674.9057,
	 673.7932, 672.6804, 671.5674, 670.4541, 669.3406, 668.2268, 667.1128, 665.9986, 664.8841, 663.7693,
	 662.6543, 661.539, 660.4235, 659.3078, 658.1918, 657.0756, 655.9591, 654.8423, 653.7254, 652.6082,
	 651.4907, 650.373, 649.255, 648.1369, 647.0184, 645.8998, 644.7808, 643.6617, 642.5423, 641.4226,
	 640.3028, 639.1826, 638.0623, 636.9417, 635.8209, 634.6998, 633.5785, 632.4569, 631.3351, 630.2131,
	 629.0908, 627.9683, 626.8456, 625.7226, 624.5994, 623.476, 622.3523, 621.2284, 620.1042, 618.9798,
	 617.8552, 616.7304, 615.6053, 614.48, 613.3544, 612.2287, 611.1027, 609.9764, 608.8499, 607.7232,
	 606.5963, 605.4691, 604.3418, 603.2141, 602.0863, 600.9582, 599.8299, 598.7014, 597.5726, 596.4436,
	 595.3144, 594.185, 593.0553, 591.9254, 590.7953, 589.6649, 588.5344, 587.4036, 586.2726, 585.1413,
	 584.0099, 582.8782, 581.7463, 580.6141, 579.4818, 578.3492, 577.2164, 576.0834, 574.9502, 573.8167,
	 572.6831, 571.5492, 570.415, 569.2807, 568.1462, 567.0114, 565.8764, 564.7412, 563.6058, 562.4702,
	 561.3343, 560.1983, 559.062, 557.9255, 556.7888, 555.6519, 554.5147, 553.3774, 552.2398, 551.102,
	 549.9641, 548.8259, 547.6875, 546.5488, 545.41, 544.271, 543.1317, 541.9923, 540.8526, 539.7127,
	 538.5726, 537.4323, 536.2918, 535.1511, 534.0102, 532.8691, 531.7277, 530.5862, 529.4445, 528.3025,
	 527.1604, 526.018, 524.8755, 523.7327, 522.5897, 521.4466, 520.3032, 519.1596, 518.0159, 516.8719,
	 515.7277, 514.5833, 513.4388, 512.294, 511.149, 510.0038, 508.8585, 507.7129, 506.5671, 505.4212,
	 504.275, 503.1287, 501.9821, 500.8353, 499.6884, 498.5413, 497.3939, 496.2464, 495.0987, 493.9508,
	 492.8027, 491.6544, 490.5059, 489.3572, 488.2083, 487.0592, 485.91, 484.7605, 483.6109, 482.4611,
	 481.311, 480.1608, 479.0105, 477.8599, 476.7091, 475.5581, 474.407, 473.2557, 472.1042, 470.9525,
	 469.8006, 468.6485, 467.4963, 466.3438, 465.1912, 464.0384, 462.8854, 461.7322, 460.5789, 459.4254,
	 458.2717, 457.1178, 455.9637, 454.8094, 453.655, 452.5004, 451.3456, 450.1906, 449.0355, 447.8802,
	 446.7247, 445.569, 444.4132, 443.2571, 442.1009, 440.9445, 439.788, 438.6313, 437.4744, 436.3173,
	 435.1601, 434.0026, 432.8451, 431.6873, 430.5294, 429.3713, 428.213, 427.0545, 425.8959, 424.7372,
	 423.5782, 422.4191, 421.2598, 420.1004, 418.9407, 417.781, 416.621, 415.4609, 414.3006, 413.1402,
	 411.9795, 410.8188, 409.6578, 408.4967, 407.3355, 406.174, 405.0125, 403.8507, 402.6888, 401.5267,
	 400.3645, 399.2021, 398.0396, 396.8768, 395.714, 394.551, 393.3878, 392.2244, 391.0609, 389.8973,
	 388.7335, 387.5695, 386.4054, 385.2411, 384.0767, 382.9121, 381.7474, 380.5825, 379.4175, 378.2523,
	 377.0869, 375.9214, 374.7558, 373.59, 372.424, 371.2579, 370.0917, 368.9253, 367.7588, 366.5921,
	 365.4253, 364.2583, 363.0912, 361.9239, 360.7565, 359.5889, 358.4212, 357.2533, 356.0853, 354.9172,
	 353.7489, 352.5805, 351.4119, 350.2432, 349.0744, 347.9054, 346.7363, 345.567, 344.3976, 343.2281,
	 342.0584, 340.8885, 339.7186, 338.5485, 337.3783, 336.2079, 335.0374, 333.8667, 332.696, 331.5251,
	 330.354, 329.1828, 328.0115, 326.8401, 325.6685, 324.4968, 323.325, 322.153, 320.9809, 319.8087,
	 318.6363, 317.4639, 316.2912, 315.1185, 313.9456, 312.7726, 311.5995, 310.4263, 309.2529, 308.0794,
	 306.9058, 305.732, 304.5581, 303.3841, 302.21, 301.0358, 299.8614, 298.6869, 297.5123, 296.3376,
	 295.1628, 293.9878, 292.8127, 291.6375, 290.4622, 289.2867, 288.1112, 286.9355, 285.7597, 284.5838,
	 283.4078, 282.2316, 281.0554, 279.879, 278.7025, 277.5259, 276.3492, 275.1724, 273.9954, 272.8184,
	 271.6412, 270.464, 269.2866, 268.1091, 266.9315, 265.7538, 264.576, 263.398, 262.22, 261.0419,
	 259.8636, 258.6853, 257.5068, 256.3283, 255.1496, 253.9708, 252.792, 251.613, 250.4339, 249.2547,
	 248.0754, 246.8961, 245.7166, 244.537, 243.3573, 242.1775, 240.9976, 239.8177, 238.6376, 237.4574,
	 236.2771, 235.0968, 233.9163, 232.7357, 231.5551, 230.3743, 229.1935, 228.0125, 226.8315, 225.6504,
	 224.4691, 223.2878, 222.1064, 220.9249, 219.7433, 218.5617, 217.3799, 216.198, 215.0161, 213.8341,
	 212.6519, 211.4697, 210.2874, 209.1051, 207.9226, 206.74, 205.5574, 204.3747, 203.1919, 202.009,
	 200.826, 199.643, 198.4598, 197.2766, 196.0933, 194.91, 193.7265, 192.543, 191.3593, 190.1756,
	 188.9919, 187.808, 186.6241, 185.4401, 184.256, 183.0719, 181.8876, 180.7033, 179.5189, 178.3345,
	 177.1499, 175.9653, 174.7807, 173.5959, 172.4111, 171.2262, 170.0413, 168.8562, 167.6711, 166.486,
	 165.3007, 164.1154, 162.93, 161.7446, 160.5591, 159.3735, 158.1879, 157.0022, 155.8164, 154.6306,
	 153.4447, 152.2587, 151.0727, 149.8866, 148.7005, 147.5143, 146.328, 145.1417, 143.9553, 142.7688,
	 141.5823, 140.3958, 139.2091, 138.0225, 136.8357, 135.6489, 134.4621, 133.2752, 132.0882, 130.9012,
	 129.7141, 128.527, 127.3398, 126.1526, 124.9653, 123.778, 122.5906, 121.4032, 120.2157, 119.0282,
	 117.8406, 116.6529, 115.4653, 114.2775, 113.0898, 111.9019, 110.7141, 109.5262, 108.3382, 107.1502,
	 105.9621, 104.7741, 103.5859, 102.3977, 101.2095, 100.0213, 98.833, 97.6446, 96.4562, 95.2678,
	 94.0793, 92.8908, 91.7023, 90.5137, 89.3251, 88.1364, 86.9477, 85.759, 84.5703, 83.3815,
	 82.1926, 81.0038, 79.8149, 78.6259, 77.437, 76.248, 75.0589, 73.8699, 72.6808, 71.4917,
	 70.3025, 69.1133, 67.9241, 66.7349, 65.5456, 64.3563, 63.167, 61.9777, 60.7883, 59.5989,
	 58.4095, 57.2201, 56.0306, 54.8411, 53.6516, 52.4621, 51.2725, 50.0829, 48.8933, 47.7037,
	 46.5141, 45.3244, 44.1347, 42.945, 41.7553, 40.5656, 39.3758, 38.1861, 36.9963, 35.8065,
	 34.6167, 33.4269, 32.237, 31.0472, 29.8573, 28.6674, 27.4775, 26.2876, 25.0977, 23.9078,
	 22.7179, 21.5279, 20.338, 19.148, 17.9581, 16.7681, 15.5781, 14.3881, 13.1981, 12.0081,
	 10.8181, 9.6281, 8.4381, 7.2481, 6.0581, 4.8681, 3.678, 2.488, 1.298, 0.10797,
	 -1.0821, -2.2721, -3.4621, -4.6521, -5.8422, -7.0322, -8.2222, -9.4122, -10.6022, -11.7922,
	 -12.9822, -14.1722, -15.3622, -16.5522, -17.7421, -18.9321, -20.1221, -21.312, -22.502, -23.6919,
	 -24.8818, -26.0717, -27.2616, -28.4515, -29.6414, -30.8313, -32.0211, -33.211, -34.4008, -35.5906,
	 -36.7804, -37.9702, -39.16, -40.3497, -41.5394, -42.7292, -43.9189, -45.1085, -46.2982, -47.4878,
	 -48.6775, -49.8671, -51.0566, -52.2462, -53.4357, -54.6253, -55.8148, -57.0042, -58.1937, -59.3831,
	 -60.5725, -61.7619, -62.9512, -64.1405, -65.3298, -66.5191, -67.7083, -68.8976, -70.0867, -71.2759,
	 -72.465, -73.6541, -74.8432, -76.0322, -77.2212, -78.4102, -79.5991, -80.788, -81.9769, -83.1658,
	 -84.3546, -85.5433, -86.7321, -87.9208, -89.1094, -90.298, -91.4866, -92.6752, -93.8637, -95.0522,
	 -96.2406, -97.429, -98.6173, -99.8056, -100.9939, -102.1821, -103.3703, -104.5585, -105.7466, -106.9346,
	 -108.1226, -109.3106, -110.4985, -111.6864, -112.8742, -114.062, -115.2498, -116.4374, -117.6251, -118.8127,
	 -120.0002, -121.1877, -122.3752, -123.5625, -124.7499, -125.9372, -127.1244, -128.3116, -129.4987, -130.6858,
	 -131.8728, -133.0598, -134.2467, -135.4336, -136.6204, -137.8071, -138.9938, -140.1805, -141.367, -142.5536,
	 -143.74, -144.9264, -146.1128, -147.299, -148.4853, -149.6714, -150.8575, -152.0435, -153.2295, -154.4154,
	 -155.6013, -156.787, -157.9728, -159.1584, -160.344, -161.5295, -162.715, -163.9003, -165.0857, -166.2709,
	 -167.4561, -168.6412, -169.8262, -171.0112, -172.1961, -173.3809, -174.5657, -175.7504, -176.935, -178.1195,
	 -179.304, -180.4884, -181.6727, -182.857, -184.0411, -185.2252, -186.4093, -187.5932, -188.7771, -189.9609,
	 -191.1446, -192.3282, -193.5117, -194.6952, -195.8786, -197.0619, -198.2452, -199.4283, -200.6114, -201.7944,
	 -202.9773, -204.1601, -205.3428, -206.5255, -207.708, -208.8905, -210.0729, -211.2552, -212.4374, -213.6196,
	 -214.8016, -215.9836, -217.1654, -218.3472, -219.5289, -220.7105, -221.892, -223.0735, -224.2548, -225.436,
	 -226.6172, -227.7982, -228.9792, -230.16, -231.3408, -232.5215, -233.7021, -234.8826, -236.063, -237.2432,
	 -238.4234, -239.6035, -240.7835, -241.9634, -243.1432, -244.3229, -245.5026, -246.6821, -247.8615, -249.0408,
	 -250.22, -251.3991, -252.578, -253.7569, -254.9357, -256.1144, -257.293, -258.4715, -259.6498, -260.8281,
	 -262.0063, -263.1843, -264.3622, -265.5401, -266.7178, -267.8954, -269.0729, -270.2503, -271.4276, -272.6048,
	 -273.7819, -274.9588, -276.1357, -277.3124, -278.489, -279.6655, -280.8419, -282.0182, -283.1943, -284.3704,
	 -285.5463, -286.7221, -287.8978, -289.0734, -290.2489, -291.4242, -292.5995, -293.7746, -294.9496, -296.1244,
	 -297.2992, -298.4738, -299.6483, -300.8227, -301.997, -303.1711, -304.3451, -305.519, -306.6928, -307.8664,
	 -309.04, -310.2134, -311.3866, -312.5598, -313.7328, -314.9057, -316.0785, -317.2511, -318.4236, -319.596,
	 -320.7682, -321.9404, -323.1123, -324.2842, -325.4559, -326.6275, -327.799, -328.9703, -330.1415, -331.3126,
	 -332.4835, -333.6543, -334.825, -335.9955, -337.1659, -338.3362, -339.5063, -340.6763, -341.8461, -343.0158,
	 -344.1854, -345.3548, -346.5241, -347.6933, -348.8623, -350.0312, -351.1999, -352.3685, -353.5369, -354.7052,
	 -355.8734, -357.0414, -358.2093, -359.377, -360.5446, -361.7121, -362.8794, -364.0465, -365.2135, -366.3804,
	 -367.5471, -368.7137, -369.8801, -371.0463, -372.2125, -373.3784, -374.5443, -375.7099, -376.8754, -378.0408,
	 -379.206, -380.3711, -381.536, -382.7008, -383.8654, -385.0298, -386.1941, -387.3583, -388.5223, -389.6861,
	 -390.8498, -392.0133, -393.1767, -394.3399, -395.503, -396.6659, -397.8286, -398.9912, -400.1536, -401.3158,
	 -402.4779, -403.6399, -404.8017, -405.9633, -407.1247, -408.286, -409.4472, -410.6081, -411.7689, -412.9296,
	 -414.0901, -415.2504, -416.4105, -417.5705, -418.7303, -419.89, -421.0494, -422.2088, -423.3679, -424.5269,
	 -425.6857, -426.8443, -428.0028, -429.1611, -430.3192, -431.4772, -432.635, -433.7926, -434.9501, -436.1073,
	 -437.2644, -438.4214, -439.5781, -440.7347, -441.8911, -443.0473, -444.2034, -445.3593, -446.515, -447.6705,
	 -448.8259, -449.9811, -451.1361, -452.2909, -453.4455, -454.6, -455.7543, -456.9084, -458.0623, -459.216,
	 -460.3696, -461.523, -462.6762, -463.8292, -464.982, -466.1347, -467.2872, -468.4395, -469.5916, -470.7435,
	 -471.8952, -473.0468, -474.1981, -475.3493, -476.5003, -477.6511, -478.8017, -479.9521, -481.1024, -482.2524,
	 -483.4023, -484.5519, -485.7014, -486.8507, -487.9998, -489.1487, -490.2974, -491.446, -492.5943, -493.7425,
	 -494.8904, -496.0382, -497.1857, -498.3331, -499.4803, -500.6273, -501.774, -502.9206, -504.067, -505.2132,
	 -506.3592, -507.505, -508.6506, -509.796, -510.9412, -512.0862, -513.2311, -514.3757, -515.5201, -516.6643,
	 -517.8083, -518.9521, -520.0957, -521.2391, -522.3823, -523.5253, -524.6681, -525.8107, -526.9531, -528.0953,
	 -529.2373, -530.3791, -531.5206, -532.662, -533.8032, -534.9441, -536.0849, -537.2254, -538.3657, -539.5059,
	 -540.6458, -541.7855, -542.925, -544.0643, -545.2033, -546.3422, -547.4809, -548.6193, -549.7576, -550.8956,
	 -552.0334, -553.171, -554.3084, -555.4455, -556.5825, -557.7193, -558.8558, -559.9921, -561.1282, -562.2641,
	 -563.3998, -564.5352, -565.6705, -566.8055, -567.9403, -569.0749, -570.2092, -571.3434, -572.4773, -573.611,
	 -574.7445, -575.8778, -577.0109, -578.1437, -579.2763, -580.4087, -581.5409, -582.6728, -583.8045, -584.936,
	 -586.0673, -587.1984, -588.3292, -589.4598, -590.5902, -591.7204, -592.8503, -593.98, -595.1095, -596.2387,
	 -597.3678, -598.4966, -599.6251, -600.7535, -601.8816, -603.0095, -604.1372, -605.2646, -606.3918, -607.5188,
	 -608.6455, -609.772, -610.8983, -612.0244, -613.1502, -614.2758, -615.4011, -616.5263, -617.6511, -618.7758,
	 -619.9002, -621.0244, -622.1484, -623.2721, -624.3956, -625.5188, -626.6419, -627.7646, -628.8872, -630.0095,
	 -631.1316, -632.2534, -633.375, -634.4963, -635.6175, -636.7383, -637.859, -638.9794, -640.0995, -641.2195,
	 -642.3391, -643.4586, -644.5778, -645.6967, -646.8155, -647.9339, -649.0522, -650.1702, -651.2879, -652.4054,
	 -653.5227, -654.6397, -655.7565, -656.873, -657.9893, -659.1053, -660.2211, -661.3366, -662.4519, -663.567,
	 -664.6818, -665.7964, -666.9107, -668.0247, -669.1385, -670.2521, -671.3654, -672.4785, -673.5913, -674.7039,
	 -675.8162, -676.9283, -678.0401, -679.1517, -680.263, -681.374, -682.4848, -683.5954, -684.7057, -685.8158,
	 -686.9256, -688.0351, -689.1444, -690.2534, -691.3622, -692.4708, -693.579, -694.687, -695.7948, -696.9023,
	 -698.0096, -699.1166, -700.2233, -701.3298, -702.436, -703.542, -704.6477, -705.7531, -706.8583, -707.9632,
	 -709.0679, -710.1723, -711.2765, -712.3803, -713.484, -714.5873, -715.6905, -716.7933, -717.8959, -718.9982,
	 -720.1003, -721.2021, -722.3036, -723.4049, -724.5059, -725.6066, -726.7071, -727.8073, -728.9072, -730.0069,
	 -731.1063, -732.2055, -733.3044, -734.403, -735.5013, -736.5994, -737.6973, -738.7948, -739.8921, -740.9891,
	 -742.0858, -743.1823, -744.2785, -745.3745, -746.4701, -747.5655, -748.6607, -749.7555, -750.8501, -751.9444,
	 -753.0385, -754.1323, -755.2258, -756.319, -757.412, -758.5047, -759.5971, -760.6892, -761.7811, -762.8727,
	 -763.964, -765.055, -766.1458, -767.2363, -768.3265, -769.4165, -770.5062, -771.5955, -772.6847, -773.7735,
	 -774.8621, -775.9504, -777.0384, -778.1261, -779.2136, -780.3007, -781.3876, -782.4743, -783.5606, -784.6467,
	 -785.7324, -786.818, -787.9032, -788.9881, -790.0728, -791.1572, -792.2413, -793.3251, -794.4086, -795.4919,
	 -796.5749, -797.6575, -798.74, -799.8221, -800.9039, -801.9855, -803.0668, -804.1478, -805.2285, -806.3089,
	 -807.389, -808.4689, -809.5484, -810.6277, -811.7067, -812.7854, -813.8639, -814.942, -816.0199, -817.0974,
	 -818.1747, -819.2517, -820.3284, -821.4048, -822.4809, -823.5568, -824.6323, -825.7076, -826.7826, -827.8572,
	 -828.9316, -830.0057, -831.0795, -832.1531, -833.2263, -834.2992, -835.3719, -836.4442, -837.5163, -838.5881,
	 -839.6596, -840.7308, -841.8017, -842.8723, -843.9426, -845.0126, -846.0823, -847.1517, -848.2209, -849.2897,
	 -850.3583, -851.4265, -852.4945, -853.5621, -854.6295, -855.6966, -856.7634, -857.8298, -858.896, -859.9619,
	 -861.0275, -862.0928, -863.1578, -864.2225, -865.2869, -866.351, -867.4148, -868.4783, -869.5415, -870.6044,
	 -871.667, -872.7293, -873.7913, -874.853, -875.9144, -876.9756, -878.0364, -879.0969, -880.1571, -881.217,
	 -882.2766, -883.3359, -884.3949, -885.4536, -886.512, -887.5701, -888.6279, -889.6854, -890.7426, -891.7994,
	 -892.856, -893.9123, -894.9683, -896.0239, -897.0793, -898.1343, -899.1891, -900.2435, -901.2977, -902.3515,
	 -903.4051, -904.4583, -905.5112, -906.5638, -907.6161, -908.6681, -909.7198, -910.7712, -911.8223, -912.8731,
	 -913.9235, -914.9737, -916.0235, -917.0731, -918.1223, -919.1712, -920.2198, -921.2681, -922.3161, -923.3638,
	 -924.4112, -925.4583, -926.505, -927.5515, -928.5976, -929.6434, -930.6889, -931.7341, -932.779, -933.8236,
	 -934.8679, -935.9118, -936.9555, -937.9988, -939.0418, -940.0845, -941.1269, -942.169, -943.2108, -944.2522,
	 -945.2934, -946.3342, -947.3747, -948.4149, -949.4548, -950.4943, -951.5336, -952.5725, -953.6112, -954.6495,
	 -955.6875, -956.7251, -957.7625, -958.7995, -959.8363, -960.8727, -961.9088, -962.9446, -963.98, -965.0152,
	 -966.05, -967.0845, -968.1187, -969.1526, -970.1861, -971.2194, -972.2523, -973.2849, -974.3172, -975.3491,
	 -976.3808, -977.4121, -978.4431, -979.4738, -980.5042, -981.5342, -982.5639, -983.5934, -984.6224, -985.6512,
	 -986.6796, -987.7078, -988.7356, -989.7631, -990.7902, -991.8171, -992.8436, -993.8698, -994.8956, -995.9212,
	 -996.9464, -997.9713, -998.9959, -1000.0202, -1001.0441, -1002.0677, -1003.091, -1004.114, -1005.1366, -1006.1589,
	 -1007.1809, -1008.2026, -1009.2239, -1010.245, -1011.2657, -1012.286, -1013.3061, -1014.3258, -1015.3452, -1016.3643,
	 -1017.383, -1018.4014, -1019.4195, -1020.4373, -1021.4547, -1022.4719, -1023.4886, -1024.5051, -1025.5212, -1026.5371,
	 -1027.5525, -1028.5677, -1029.5825, -1030.597, -1031.6112, -1032.625, -1033.6385, -1034.6517, -1035.6646, -1036.6771,
	 -1037.6893, -1038.7012, -1039.7127, -1040.724, -1041.7348, -1042.7454, -1043.7556, -1044.7655, -1045.7751, -1046.7843,
	 -1047.7932, -1048.8018, -1049.8101, -1050.818, -1051.8256, -1052.8328, -1053.8397, -1054.8463, -1055.8526, -1056.8585,
	 -1057.8641, -1058.8694, -1059.8743, -1060.8789, -1061.8832, -1062.8872, -1063.8908, -1064.894, -1065.897, -1066.8996,
	 -1067.9019, -1068.9038, -1069.9054, -1070.9067, -1071.9077, -1072.9083, -1073.9086, -1074.9085, -1075.9081, -1076.9074,
	 -1077.9063, -1078.905, -1079.9032, -1080.9012, -1081.8988, -1082.8961, -1083.893, -1084.8896, -1085.8859, -1086.8818,
	 -1087.8774, -1088.8727, -1089.8676, -1090.8622, -1091.8565, -1092.8504, -1093.844, -1094.8372, -1095.8301, -1096.8227,
	 -1097.8149, -1098.8068, -1099.7984, -1100.7896, -1101.7805, -1102.7711, -1103.7613, -1104.7512, -1105.7407, -1106.73,
	 -1107.7188, -1108.7074, -1109.6956, -1110.6834, -1111.6709, -1112.6581, -1113.645, -1114.6315, -1115.6176, -1116.6035,
	 -1117.5889, -1118.5741, -1119.5589, -1120.5434, -1121.5275, -1122.5113, -1123.4948, -1124.4779, -1125.4607, -1126.4431,
	 -1127.4252, -1128.407, -1129.3884, -1130.3695, -1131.3502, -1132.3306, -1133.3107, -1134.2904, -1135.2698, -1136.2488,
	 -1137.2275, -1138.2058, -1139.1839, -1140.1615, -1141.1389, -1142.1159, -1143.0925, -1144.0688, -1145.0448, -1146.0204,
	 -1146.9957, -1147.9706, -1148.9453, -1149.9195, -1150.8934, -1151.867, -1152.8402, -1153.8131, -1154.7857, -1155.7579,
	 -1156.7298, -1157.7013, -1158.6725, -1159.6433, -1160.6138, -1161.5839, -1162.5538, -1163.5232, -1164.4923, -1165.4611,
	 -1166.4296, -1167.3977, -1168.3654, -1169.3328, -1170.2999, -1171.2666, -1172.233, -1173.199, -1174.1647, -1175.13,
	 -1176.095, -1177.0597, -1178.024, -1178.9879, -1179.9516, -1180.9148, -1181.8778, -1182.8404, -1183.8026, -1184.7645,
	 -1185.7261, -1186.6873, -1187.6481, -1188.6086, -1189.5688, -1190.5286, -1191.4881, -1192.4473, -1193.4061, -1194.3645,
	 -1195.3226, -1196.2804, -1197.2378, -1198.1948, -1199.1515, -1200.1079, -1201.0639, -1202.0196, -1202.975, -1203.9299,
	 -1204.8846, -1205.8389, -1206.7928, -1207.7464, -1208.6997, -1209.6526, -1210.6051, -1211.5574, -1212.5092, -1213.4607,
	 -1214.4119, -1215.3627, -1216.3132, -1217.2634, -1218.2131, -1219.1626, -1220.1117, -1221.0604, -1222.0088, -1222.9569,
	 -1223.9046, -1224.8519, -1225.7989, -1226.7456, -1227.6919, -1228.6378, -1229.5835, -1230.5287, -1231.4736, -1232.4182,
	 -1233.3624, -1234.3063, -1235.2498, -1236.193, -1237.1358, -1238.0783, -1239.0205, -1239.9622, -1240.9037, -1241.8448,
	 -1242.7855, -1243.7259, -1244.6659, -1245.6056, -1246.545, -1247.484, -1248.4226, -1249.3609, -1250.2988, -1251.2364,
	 -1252.1737, -1253.1106, -1254.0471, -1254.9833, -1255.9192, -1256.8547, -1257.7898, -1258.7246, -1259.6591, -1260.5932,
	 -1261.527, -1262.4604, -1263.3934, -1264.3261, -1265.2585, -1266.1905, -1267.1221, -1268.0535, -1268.9844, -1269.915,
	 -1270.8453, -1271.7752, -1272.7047, -1273.6339, -1274.5628, -1275.4913, -1276.4195, -1277.3473, -1278.2747, -1279.2018,
	 -1280.1286, -1281.055, -1281.9811, -1282.9068, -1283.8321, -1284.7571, -1285.6818, -1286.6061, -1287.53, -1288.4536,
	 -1289.3769, -1290.2998, -1291.2223, -1292.1445, -1293.0664, -1293.9879, -1294.909, -1295.8298, -1296.7502, -1297.6703,
	 -1298.5901, -1299.5095, -1300.4285, -1301.3472, -1302.2655, -1303.1835, -1304.1012, -1305.0184, -1305.9354, -1306.852,
	 -1307.7682, -1308.6841, -1309.5996, -1310.5148, -1311.4296, -1312.3441, -1313.2582, -1314.172, -1315.0854, -1315.9985,
	 -1316.9112, -1317.8235, -1318.7356, -1319.6472, -1320.5585, -1321.4695, -1322.3801, -1323.2904, -1324.2003, -1325.1098,
	 -1326.019, -1326.9279, -1327.8364, -1328.7445, -1329.6523, -1330.5598, -1331.4669, -1332.3736, -1333.28, -1334.186,
	 -1335.0917, -1335.997, -1336.902, -1337.8067, -1338.7109, -1339.6149, -1340.5184, -1341.4217, -1342.3245, -1343.227,
	 -1344.1292, -1345.031, -1345.9325, -1346.8336, -1347.7344, -1348.6348, -1349.5348, -1350.4345, -1351.3339, -1352.2329,
	 -1353.1315, -1354.0298, -1354.9278, -1355.8254, -1356.7226, -1357.6195, -1358.516, -1359.4122, -1360.3081, -1361.2035,
	 -1362.0987, -1362.9934, -1363.8879, -1364.7819, -1365.6757, -1366.569, -1367.462, -1368.3547, -1369.247, -1370.139,
	 -1371.0306, -1371.9219, -1372.8128, -1373.7033, -1374.5935, -1375.4834, -1376.3729, -1377.262, -1378.1508, -1379.0392,
	 -1379.9273, -1380.8151, -1381.7024, -1382.5895, -1383.4762, -1384.3625, -1385.2485, -1386.1341, -1387.0194, -1387.9043,
	 -1388.7889, -1389.6731, -1390.5569, -1391.4405, -1392.3236, -1393.2064, -1394.0889, -1394.971, -1395.8528, -1396.7342,
	 -1397.6152, -1398.4959, -1399.3763, -1400.2562, -1401.1359, -1402.0152, -1402.8941, -1403.7727, -1404.651, -1405.5288,
	 -1406.4064, -1407.2836, -1408.1604, -1409.0369, -1409.913, -1410.7888, -1411.6642, -1412.5393, -1413.414, -1414.2883,
	 -1415.1624, -1416.036, -1416.9093, -1417.7823, -1418.6549, -1419.5272, -1420.3991, -1421.2706, -1422.1419, -1423.0127,
	 -1423.8832, -1424.7534, -1425.6232, -1426.4926, -1427.3617, -1428.2305, -1429.0988, -1429.9669, -1430.8346, -1431.7019,
	 -1432.5689, -1433.4356, -1434.3018, -1435.1678, -1436.0334, -1436.8986, -1437.7635, -1438.628, -1439.4922, -1440.356,
	 -1441.2195, -1442.0826, -1442.9454, -1443.8078, -1444.6699, -1445.5316, -1446.393, -1447.254, -1448.1147, -1448.975,
	 -1449.835, -1450.6946, -1451.5539, -1452.4128, -1453.2714, -1454.1296, -1454.9875, -1455.845, -1456.7022, -1457.559,
	 -1458.4154, -1459.2716, -1460.1273, -1460.9827, -1461.8378, -1462.6925, -1463.5469, -1464.4009, -1465.2546, -1466.1079,
	 -1466.9609, -1467.8135, -1468.6657, -1469.5176, -1470.3692, -1471.2204, -1472.0713, -1472.9218, -1473.772, -1474.6218,
	 -1475.4713, -1476.3204, -1477.1691, -1478.0176, -1478.8656, -1479.7133, -1480.5607, -1481.4077, -1482.2544, -1483.1007,
	 -1483.9467, -1484.7923, -1485.6376, -1486.4825, -1487.3271, -1488.1713, -1489.0152, -1489.8587, -1490.7019, -1491.5447,
	 -1492.3872, -1493.2293, -1494.0711, -1494.9126, -1495.7536, -1496.5944, -1497.4348, -1498.2748, -1499.1145, -1499.9538,
	 -1500.7928, -1501.6315, -1502.4698, -1503.3077, -1504.1453, -1504.9826, -1505.8195, -1506.656, -1507.4922, -1508.3281,
	 -1509.1636, -1509.9988, -1510.8336, -1511.6681, -1512.5022, -1513.3359, -1514.1694, -1515.0024, -1515.8352, -1516.6676,
	 -1517.4996, -1518.3313, -1519.1626, -1519.9936, -1520.8242, -1521.6545, -1522.4845, -1523.3141, -1524.1433, -1524.9723,
	 -1525.8008, -1526.629, -1527.4569, -1528.2844, -1529.1116, -1529.9384, -1530.7649, -1531.591, -1532.4168, -1533.2422,
	 -1534.0673, -1534.8921, -1535.7165, -1536.5405, -1537.3642, -1538.1876, -1539.0106, -1539.8333, -1540.6556, -1541.4776,
	 -1542.2992, -1543.1205, -1543.9414, -1544.762, -1545.5823, -1546.4022, -1547.2217, -1548.0409, -1548.8598, -1549.6783,
	 -1550.4965, -1551.3143, -1552.1318, -1552.949, -1553.7657, -1554.5822, -1555.3983, -1556.2141, -1557.0295, -1557.8445,
	 -1558.6593, -1559.4736, -1560.2877, -1561.1014, -1561.9147, -1562.7277, -1563.5404, -1564.3527, -1565.1646, -1565.9763,
	 -1566.7875, -1567.5985, -1568.4091, -1569.2193, -1570.0292, -1570.8388, -1571.648, -1572.4568, -1573.2654, -1574.0735,
	 -1574.8814, -1575.6889, -1576.496, -1577.3028, -1578.1093, -1578.9154, -1579.7212, -1580.5266, -1581.3317, -1582.1365,
	 -1582.9409, -1583.745, -1584.5487, -1585.3521, -1586.1551, -1586.9578, -1587.7601, -1588.5621, -1589.3638, -1590.1651,
	 -1590.9661, -1591.7668, -1592.5671, -1593.367, -1594.1666, -1594.9659, -1595.7648, -1596.5634, -1597.3617, -1598.1596,
	 -1598.9571, -1599.7543, -1600.5512, -1601.3478, -1602.144, -1602.9398, -1603.7353, -1604.5305, -1605.3253, -1606.1198,
	 -1606.914, -1607.7078, -1608.5013, -1609.2944, -1610.0872, -1610.8796, -1611.6717, -1612.4635, -1613.2549, -1614.046,
	 -1614.8368, -1615.6272, -1616.4172, -1617.207, -1617.9964, -1618.7854, -1619.5741, -1620.3625, -1621.1505, -1621.9382,
	 -1622.7256, -1623.5126, -1624.2992, -1625.0856, -1625.8716, -1626.6572, -1627.4425, -1628.2275, -1629.0121, -1629.7964,
	 -1630.5804, -1631.364, -1632.1473, -1632.9303, -1633.7129, -1634.4951, -1635.2771, -1636.0587, -1636.8399, -1637.6208,
	 -1638.4014, -1639.1817, -1639.9616, -1640.7411, -1641.5204, -1642.2993, -1643.0778, -1643.856, -1644.6339, -1645.4114,
	 -1646.1887, -1646.9655, -1647.7421, -1648.5183, -1649.2941, -1650.0696, -1650.8448, -1651.6197, -1652.3942, -1653.1684,
	 -1653.9422, -1654.7157, -1655.4889, -1656.2617, -1657.0342, -1657.8064, -1658.5782, -1659.3497, -1660.1208, -1660.8917,
	 -1661.6621, -1662.4323, -1663.2021, -1663.9716, -1664.7407, -1665.5095, -1666.278, -1667.0462, -1667.814, -1668.5814,
	 -1669.3486, -1670.1154, -1670.8818, -1671.648, -1672.4138, -1673.1792, -1673.9444, -1674.7092, -1675.4736, -1676.2378,
	 -1677.0016, -1677.765, -1678.5281, -1679.2909, -1680.0534, -1680.8155, -1681.5773, -1682.3388, -1683.0999, -1683.8607,
	 -1684.6212, -1685.3813, -1686.1411, -1686.9006, -1687.6597, -1688.4185, -1689.177, -1689.9351, -1690.6929, -1691.4504,
	 -1692.2076, -1692.9644, -1693.7209, -1694.477, -1695.2328, -1695.9883, -1696.7435, -1697.4983, -1698.2528, -1699.0069,
	 -1699.7608, -1700.5143, -1701.2674, -1702.0203, -1702.7728, -1703.525, -1704.2768, -1705.0283, -1705.7795, -1706.5304,
	 -1707.2809, -1708.0311, -1708.781, -1709.5305, -1710.2797, -1711.0286, -1711.7771, -1712.5254, -1713.2732, -1714.0208,
	 -1714.768, -1715.5149, -1716.2615, -1717.0078, -1717.7537, -1718.4993, -1719.2445, -1719.9895, -1720.7341, -1721.4783,
	 -1722.2223, -1722.9659, -1723.7092, -1724.4522, -1725.1948, -1725.9371, -1726.6791, -1727.4208, -1728.1621, -1728.9031,
	 -1729.6438, -1730.3841, -1731.1241, -1731.8638, -1732.6032, -1733.3422, -1734.0809, -1734.8193, -1735.5574, -1736.2951,
	 -1737.0325, -1737.7696, -1738.5063, -1739.2428, -1739.9789, -1740.7147, -1741.4501, -1742.1852, -1742.92, -1743.6545,
	 -1744.3887, -1745.1225, -1745.856, -1746.5892, -1747.322, -1748.0546, -1748.7868, -1749.5186, -1750.2502, -1750.9814,
	 -1751.7123, -1752.4429, -1753.1732, -1753.9031, -1754.6327, -1755.362, -1756.091, -1756.8196, -1757.5479, -1758.2759,
	 -1759.0036, -1759.7309, -1760.458, -1761.1847, -1761.911, -1762.6371, -1763.3628, -1764.0882, -1764.8133, -1765.5381,
	 -1766.2625, -1766.9867, -1767.7105, -1768.434, -1769.1571, -1769.8799, -1770.6025, -1771.3247, -1772.0465, -1772.7681,
	 -1773.4893, -1774.2102, -1774.9308, -1775.6511, -1776.371, -1777.0907, -1777.81, -1778.5289, -1779.2476, -1779.966,
	 -1780.684, -1781.4017, -1782.1191, -1782.8361, -1783.5529, -1784.2693, -1784.9854, -1785.7012, -1786.4167, -1787.1318,
	 -1787.8467, -1788.5612, -1789.2754, -1789.9893, -1790.7028, -1791.4161, -1792.129, -1792.8416, -1793.5539, -1794.2658,
	 -1794.9775, -1795.6888, -1796.3998, -1797.1105, -1797.8209, -1798.531, -1799.2407, -1799.9501, -1800.6592, -1801.368,
	 -1802.0765, -1802.7847, -1803.4925, -1804.2, -1804.9073, -1805.6142, -1806.3207, -1807.027, -1807.7329, -1808.4386,
	 -1809.1439, -1809.8489, -1810.5536, -1811.2579, -1811.962, -1812.6657, -1813.3692, -1814.0723, -1814.7751, -1815.4775,
	 -1816.1797, -1816.8815, -1817.5831, -1818.2843, -1818.9852, -1819.6858, -1820.3861, -1821.086, -1821.7857, -1822.485,
	 -1823.1841, -1823.8828, -1824.5812, -1825.2793, -1825.977, -1826.6745, -1827.3716, -1828.0685, -1828.765, -1829.4612,
	 -1830.1571, -1830.8527, -1831.5479, -1832.2429, -1832.9376, -1833.6319, -1834.3259, -1835.0196, -1835.713, -1836.4061,
	 -1837.0989, -1837.7914, -1838.4835, -1839.1754, -1839.8669, -1840.5581, -1841.249, -1841.9396, -1842.6299, -1843.3199,
	 -1844.0096, -1844.6989, -1845.388, -1846.0767, -1846.7652, -1847.4533, -1848.1411, -1848.8286, -1849.5158, -1850.2027,
	 -1850.8893, -1851.5755, -1852.2615, -1852.9471, -1853.6325, -1854.3175, -1855.0022, -1855.6867, -1856.3708, -1857.0546,
	 -1857.7381, -1858.4213, -1859.1041, -1859.7867, -1860.469, -1861.1509, -1861.8326, -1862.5139, -1863.1949, -1863.8757,
	 -1864.5561, -1865.2362, -1865.916, -1866.5955, -1867.2747, -1867.9536, -1868.6322, -1869.3105, -1869.9884, -1870.6661,
	 -1871.3435, -1872.0205, -1872.6973, -1873.3737, -1874.0498, -1874.7257, -1875.4012, -1876.0764, -1876.7514, -1877.426,
	 -1878.1003, -1878.7743, -1879.448, -1880.1214, -1880.7945, -1881.4673, -1882.1398, -1882.8119, -1883.4838, -1884.1554,
	 -1884.8267, -1885.4977, -1886.1683, -1886.8387, -1887.5087, -1888.1785, -1888.848, -1889.5171, -1890.186, -1890.8545,
	 -1891.5228, -1892.1907, -1892.8584, -1893.5257, -1894.1927, -1894.8595, -1895.5259, -1896.1921, -1896.8579, -1897.5234,
	 -1898.1887, -1898.8536, -1899.5182, -1900.1826, -1900.8466, -1901.5103, -1902.1737, -1902.8369, -1903.4997, -1904.1622,
	 -1904.8245, -1905.4864, -1906.148, -1906.8094, -1907.4704, -1908.1311, -1908.7916, -1909.4517, -1910.1115, -1910.7711,
	 -1911.4303, -1912.0893, -1912.7479, -1913.4063, -1914.0643, -1914.7221, -1915.3795, -1916.0367, -1916.6935, -1917.3501,
	 -1918.0063, -1918.6623, -1919.318, -1919.9734, -1920.6284, -1921.2832, -1921.9377, -1922.5919, -1923.2458, -1923.8993,
	 -1924.5526, -1925.2056, -1925.8583, -1926.5108, -1927.1629, -1927.8147, -1928.4662, -1929.1174, -1929.7684, -1930.419,
	 -1931.0693, -1931.7194, -1932.3691, -1933.0186, -1933.6678, -1934.3166, -1934.9652, -1935.6135, -1936.2615, -1936.9092,
	 -1937.5566, -1938.2037, -1938.8505, -1939.497, -1940.1432, -1940.7891, -1941.4348, -1942.0801, -1942.7252, -1943.3699,
	 -1944.0144, -1944.6586, -1945.3025, -1945.9461, -1946.5894, -1947.2324, -1947.8751, -1948.5175, -1949.1596, -1949.8015,
	 -1950.443, -1951.0843, -1951.7252, -1952.3659, -1953.0063, -1953.6464, -1954.2862, -1954.9257, -1955.5649, -1956.2039,
	 -1956.8425, -1957.4809, -1958.1189, -1958.7567, -1959.3942, -1960.0314, -1960.6683, -1961.3049, -1961.9412, -1962.5773,
	 -1963.213, -1963.8485, -1964.4836, -1965.1185, -1965.7531, -1966.3874, -1967.0214, -1967.6552, -1968.2886, -1968.9218,
	 -1969.5546, -1970.1872, -1970.8195, -1971.4515, -1972.0832, -1972.7146, -1973.3458, -1973.9766, -1974.6072, -1975.2375,
	 -1975.8675, -1976.4972, -1977.1266, -1977.7558, -1978.3846, -1979.0132, -1979.6414, -1980.2694, -1980.8972, -1981.5246,
	 -1982.1517, -1982.7786, -1983.4051, -1984.0314, -1984.6574, -1985.2831, -1985.9086, -1986.5337, -1987.1586, -1987.7831,
	 -1988.4074, -1989.0314, -1989.6552, -1990.2786, -1990.9018, -1991.5246, -1992.1472, -1992.7695, -1993.3916, -1994.0133,
	 -1994.6348, -1995.2559, -1995.8768, -1996.4974, -1997.1178, -1997.7378, -1998.3576, -1998.9771, -1999.5963, -2000.2152,
	 -2000.8338, -2001.4522, -2002.0703, -2002.688, -2003.3056, -2003.9228, -2004.5397, -2005.1564, -2005.7728, -2006.3889,
	 -2007.0047, -2007.6203, -2008.2356, -2008.8505, -2009.4653, -2010.0797, -2010.6938, -2011.3077, -2011.9213, -2012.5346,
	 -2013.1476, -2013.7604, -2014.3729, -2014.9851, -2015.597, -2016.2086, -2016.82, -2017.4311, -2018.0419, -2018.6524,
	 -2019.2626, -2019.8726, -2020.4823, -2021.0917, -2021.7009, -2022.3097, -2022.9183, -2023.5266, -2024.1346, -2024.7424,
	 -2025.3499, -2025.9571, -2026.564, -2027.1706, -2027.777, -2028.3831, -2028.9889, -2029.5945, -2030.1997, -2030.8047,
	 -2031.4094, -2032.0139, -2032.618, -2033.2219, -2033.8255, -2034.4289, -2035.032, -2035.6347, -2036.2373, -2036.8395,
	 -2037.4415, -2038.0432, -2038.6446, -2039.2457, -2039.8466, -2040.4472, -2041.0475, -2041.6476, -2042.2474, -2042.8469,
	 -2043.4461, -2044.0451, -2044.6438, -2045.2422, -2045.8403, -2046.4382, -2047.0358, -2047.6331, -2048.2302, -2048.827,
	 -2049.4235, -2050.0197, -2050.6157, -2051.2114, -2051.8068, -2052.402, -2052.9969, -2053.5915, -2054.1858, -2054.7799,
	 -2055.3737, -2055.9672, -2056.5605, -2057.1535, -2057.7462, -2058.3386, -2058.9308, -2059.5227, -2060.1144, -2060.7057,
	 -2061.2968, -2061.8877, -2062.4782, -2063.0685, -2063.6586, -2064.2483, -2064.8378, -2065.427, -2066.016, -2066.6047,
	 -2067.1931, -2067.7813, -2068.3691, -2068.9567, -2069.5441, -2070.1312, -2070.718, -2071.3045, -2071.8908, -2072.4768,
	 -2073.0626, -2073.648, -2074.2333, -2074.8182, -2075.4029, -2075.9873, -2076.5714, -2077.1553, -2077.7389, -2078.3223,
	 -2078.9054, -2079.4882, -2080.0707, -2080.653, -2081.2351, -2081.8168, -2082.3983, -2082.9795, -2083.5605, -2084.1412,
	 -2084.7216, -2085.3018, -2085.8817, -2086.4614, -2087.0407, -2087.6198, -2088.1987, -2088.7773, -2089.3556, -2089.9337,
	 -2090.5115, -2091.089, -2091.6663, -2092.2433, -2092.82, -2093.3965, -2093.9728, -2094.5487, -2095.1244, -2095.6998,
	 -2096.275, -2096.8499, -2097.4246, -2097.999, -2098.5731, -2099.147, -2099.7206, -2100.2939, -2100.867, -2101.4398,
	 -2102.0124, -2102.5847, -2103.1567, -2103.7285, -2104.3, -2104.8713, -2105.4423, -2106.0131, -2106.5835, -2107.1538,
	 -2107.7237, -2108.2934, -2108.8629, -2109.4321, -2110.001, -2110.5697, -2111.1381, -2111.7062, -2112.2741, -2112.8417,
	 -2113.4091, -2113.9762, -2114.5431, -2115.1097, -2115.6761, -2116.2421, -2116.808, -2117.3735, -2117.9389, -2118.5039,
	 -2119.0687, -2119.6333, -2120.1976, -2120.7616, -2121.3254, -2121.8889, -2122.4521, -2123.0152, -2123.5779, -2124.1404,
	 -2124.7026, -2125.2646, -2125.8263, -2126.3878, -2126.949, -2127.51, -2128.0707, -2128.6312, -2129.1914, -2129.7513,
	 -2130.311, -2130.8704, -2131.4296, -2131.9885, -2132.5472, -2133.1056, -2133.6638, -2134.2217, -2134.7794, -2135.3368,
	 -2135.8939, -2136.4508, -2137.0075, -2137.5638, -2138.12, -2138.6759, -2139.2315, -2139.7869, -2140.342, -2140.8969,
	 -2141.4515, -2142.0059, -2142.56, -2143.1139, -2143.6675, -2144.2209, -2144.774, -2145.3268, -2145.8795, -2146.4318,
	 -2146.9839, -2147.5358, -2148.0874, -2148.6388, -2149.1899, -2149.7407, -2150.2913, -2150.8417, -2151.3918, -2151.9417,
	 -2152.4913, -2153.0406, -2153.5897, -2154.1386, -2154.6872, -2155.2356, -2155.7837, -2156.3316, -2156.8792, -2157.4265,
	 -2157.9737, -2158.5205, -2159.0672, -2159.6135, -2160.1597, -2160.7055, -2161.2512, -2161.7966, -2162.3417, -2162.8866,
	 -2163.4312, -2163.9756, -2164.5198, -2165.0637, -2165.6073, -2166.1507, -2166.6939, -2167.2368, -2167.7795, -2168.3219,
	 -2168.8641, -2169.406, -2169.9477, -2170.4891, -2171.0303, -2171.5713, -2172.112, -2172.6525, -2173.1927, -2173.7326,
	 -2174.2724, -2174.8118, -2175.3511, -2175.8901, -2176.4288, -2176.9673, -2177.5056, -2178.0436, -2178.5814, -2179.1189,
	 -2179.6562, -2180.1932, -2180.73, -2181.2666, -2181.8029, -2182.3389, -2182.8748, -2183.4103, -2183.9457, -2184.4808,
	 -2185.0156, -2185.5502, -2186.0846, -2186.6187, -2187.1526, -2187.6863, -2188.2197, -2188.7528, -2189.2857, -2189.8184,
	 -2190.3509, -2190.8831, -2191.415, -2191.9467, -2192.4782, -2193.0094, -2193.5404, -2194.0712, -2194.6017, -2195.132,
	 -2195.662, -2196.1918, -2196.7213, -2197.2506, -2197.7797, -2198.3085, -2198.8371, -2199.3655, -2199.8936, -2200.4215,
	 -2200.9491, -2201.4765, -2202.0037, -2202.5306, -2203.0573, -2203.5837, -2204.1099, -2204.6359, -2205.1616, -2205.6871,
	 -2206.2124, -2206.7374, -2207.2622, -2207.7867, -2208.3111, -2208.8351, -2209.359, -2209.8826, -2210.4059, -2210.929,
	 -2211.4519, -2211.9746, -2212.497, -2213.0192, -2213.5411, -2214.0628, -2214.5843, -2215.1055, -2215.6265, -2216.1473,
	 -2216.6678, -2217.1881, -2217.7082, -2218.228, -2218.7476, -2219.2669, -2219.7861, -2220.3049, -2220.8236, -2221.342,
	 -2221.8602, -2222.3782, -2222.8959, -2223.4133, -2223.9306, -2224.4476, -2224.9644, -2225.4809, -2225.9973, -2226.5133,
	 -2227.0292, -2227.5448, -2228.0602, -2228.5753, -2229.0903, -2229.6049, -2230.1194, -2230.6336, -2231.1476, -2231.6614,
	 -2232.1749, -2232.6882, -2233.2013, -2233.7141, -2234.2267, -2234.7391, -2235.2512, -2235.7631, -2236.2748, -2236.7862,
	 -2237.2975, -2237.8084, -2238.3192, -2238.8297, -2239.34, -2239.8501, -2240.3599, -2240.8695, -2241.3789, -2241.888,
	 -2242.397, -2242.9057, -2243.4141, -2243.9223, -2244.4303, -2244.9381, -2245.4457, -2245.953, -2246.4601, -2246.9669,
	 -2247.4736, -2247.98, -2248.4861, -2248.9921, -2249.4978, -2250.0033, -2250.5085, -2251.0136, -2251.5184, -2252.023,
	 -2252.5273, -2253.0315, -2253.5354, -2254.039, -2254.5425, -2255.0457, -2255.5487, -2256.0515, -2256.554, -2257.0563,
	 -2257.5584, -2258.0603, -2258.5619, -2259.0633, -2259.5645, -2260.0655, -2260.5662, -2261.0667, -2261.567, -2262.0671,
	 -2262.5669, -2263.0665, -2263.5659, -2264.0651, -2264.564, -2265.0627, -2265.5612, -2266.0595, -2266.5575, -2267.0554,
	 -2267.553, -2268.0503, -2268.5475, -2269.0444, -2269.5411, -2270.0376, -2270.5338, -2271.0299, -2271.5257, -2272.0213,
	 -2272.5166, -2273.0118, -2273.5067, -2274.0014, -2274.4959, -2274.9901, -2275.4842, -2275.978, -2276.4716, -2276.965,
	 -2277.4581, -2277.951, -2278.4437, -2278.9362, -2279.4285, -2279.9205, -2280.4123, -2280.904, -2281.3953, -2281.8865,
	 -2282.3774, -2282.8682, -2283.3587, -2283.8489, -2284.339, -2284.8288, -2285.3185, -2285.8079, -2286.2971, -2286.786,
	 -2287.2748, -2287.7633, -2288.2516, -2288.7397, -2289.2276, -2289.7152, -2290.2027, -2290.6899, -2291.1769, -2291.6636,
	 -2292.1502, -2292.6365, -2293.1227, -2293.6086, -2294.0943, -2294.5797, -2295.065, -2295.55, -2296.0349, -2296.5195,
	 -2297.0039, -2297.488, -2297.972, -2298.4557, -2298.9393, -2299.4226, -2299.9056, -2300.3885, -2300.8712, -2301.3536,
	 -2301.8359, -2302.3179, -2302.7997, -2303.2812, -2303.7626, -2304.2438, -2304.7247, -2305.2054, -2305.6859, -2306.1662,
	 -2306.6463, -2307.1261, -2307.6058, -2308.0852, -2308.5644, -2309.0435, -2309.5222, -2310.0008, -2310.4792, -2310.9573,
	 -2311.4353, -2311.913, -2312.3905, -2312.8678, -2313.3449, -2313.8218, -2314.2984, -2314.7749, -2315.2511, -2315.7271,
	 -2316.2029, -2316.6785, -2317.1539, -2317.6291, -2318.104, -2318.5788, -2319.0533, -2319.5276, -2320.0018, -2320.4757};

volatile bool dataReady = false;
volatile bool tick = false;
volatile bool SHARP_valid;
volatile uint32_t previousmotorinput = 0;
volatile uint32_t actualmotorinput = 0;
bool stop = false;
bool stop_deadman = false;
bool stop_drone = false;
bool stop_gyalogos = false;
bool stop_cel = false;
volatile bool stop_radios_modulra_var = true; ////
volatile uint8_t radios_uart_vevo = 0;
int32_t motorpulsePWM;
volatile uint32_t timestamp = 0;
volatile uint32_t actualencoderval=0;
volatile bool dovelocitymeasurement=false;

uint8_t uartcsomagokszama_vonalszenzor=10;
uint8_t merre_menjunk_ha_van_oldalfal=0;
uint32_t utvalaszto_encoder_start=0;
bool stop_libikoka=false;

bool stop_hordo=false;

/*Encoder vars*/
uint32_t encoder1;
HAL_TIM_StateTypeDef state;
uint32_t encoderprev=0;
int32_t encoderdiff;
uint32_t dir;
int32_t velocity;
//int32_t filteredvelocity;
//int32_t filteredvelocitydiff;
//int32_t velocityarray[4]={0,0,0,0}; //Kis csalas, akkor jo, ha VELOCITY_FILTER_DEPTH = 4
//uint32_t velocityabs;
/* SHARP vars */
uint16_t SHARPData[3] = {0,0,0};
int32_t SHARPData2[3] = {0,0,0};
int32_t SHARP_F = 0;
int32_t SHARP_R = 0;
int32_t SHARP_L = 0;
int32_t SHARP_F_ARRAY[20] = {0,0,0,0,0,0,0,0,0,0,0,0,0,0,0,0,0,0,0,0};
int32_t SHARP_R_ARRAY[20] = {0,0,0,0,0,0,0,0,0,0,0,0,0,0,0,0,0,0,0,0};
int32_t SHARP_L_ARRAY[20] = {0,0,0,0,0,0,0,0,0,0,0,0,0,0,0,0,0,0,0,0};
/* UART-on kuldento string */
uint8_t string[20] = {0,0,0,0,0,0,0,0,0,0,0,0,0,0,0,0,0,0,0,0};

uint8_t vonalobjektumtipus=SIMA_VEZETOVONAL;
volatile bool vonalat_ignoraljuk=false;
volatile bool oldalobjektumfigyelest_ignoraljuk=false;
bool voltmarkorforgo=false;

bool sebszab = true;

//UART, vonalszenzor
volatile bool vonalszenzor_uzenetjott=false;
/* USER CODE END PV */

void SystemClock_Config(void);
void Error_Handler(void);

/* USER CODE BEGIN PFP */
/* Private function prototypes -----------------------------------------------*/
uint32_t reverse_byte_order_32(uint32_t value);
void drone();
void gyalogos();
void korforgo();
void hordo();
void libikoka();
void oldal_objektum_eszeleles();
void WMAfilter(int32_t* filteredval, int32_t* newelement, int32_t* array, uint32_t filter_depth);
void send16bitdecimal_to_uart(UART_HandleTypeDef* huart, uint16_t* data,uint32_t Timeout);
void allapotteres_szabalyozo(uint16_t* pozicio, int16_t* orientacio, int32_t* sebesseg, uint32_t* PWMeredmeny);
void sebessegszabalyozo(int32_t mmpersec);
void vonal_objektum_eszleles_ugyessegi (uint8_t vonaltipus, uint8_t* objektumtipus);
void celfigyeles(uint8_t vonaltipus);

/* USER CODE END PFP */

/* USER CODE BEGIN 0 */
void HAL_ADC_ConvCpltCallback(ADC_HandleTypeDef* hadc)
{
	if (hadc->Instance == ADC1)
		SHARP_valid = true;
}
void HAL_TIM_IC_CaptureCallback(TIM_HandleTypeDef* htim)
{
	if (htim->Instance == TIM4)
	{
		previousmotorinput = actualmotorinput;
		actualmotorinput = HAL_TIM_ReadCapturedValue(&htim4,TIM_CHANNEL_1);
		__HAL_TIM_SET_COUNTER(&htim4,0);
	}
}
void HAL_TIM_PeriodElapsedCallback(TIM_HandleTypeDef *htim)
{
	/*if(htim->Instance == TIM6)
	{

	}*/
	if(htim->Instance == TIM7)
	{
		timestamp++;
		actualencoderval=HAL_TIM_ReadCapturedValue(&htim2, TIM_CHANNEL_1);
		//dovelocitymeasurement=true;
		tick = true;

	}
}

void HAL_UART_RxCpltCallback(UART_HandleTypeDef *huart)
{
	/*if(huart->Instance == USART2)
	{
		HAL_UART_Receive_IT(huart, (uint8_t *) inputStream, sizeof(inputStream));
		dataReady = true;
	}*/
	if (huart->Instance ==USART1)
	{
		vonalszenzor_uzenetjott=true;
	}
	if(huart->Instance==UART5)
	{
		if(radios_uart_vevo==0x30)
			stop_radios_modulra_var=false;
	}
}
void HAL_UART_ErrorCallback(UART_HandleTypeDef *huart)
{
	if (huart->Instance ==USART1)
	{
	    if (huart->ErrorCode == HAL_UART_ERROR_ORE)//Néha random overrun hiba, ekkor kinullázuk
	    {
	            // remove the error condition
	            huart->ErrorCode = HAL_UART_ERROR_NONE;
	            // set the correct state, so that the UART_RX_IT works correctly
	            huart->gState = HAL_UART_STATE_BUSY_RX;
	    }
	}
	if(huart -> Instance == UART5)
	{
		if (huart->ErrorCode == HAL_UART_ERROR_ORE)//Néha random overrun hiba, ekkor kinullázuk
		{
				// remove the error condition
				huart->ErrorCode = HAL_UART_ERROR_NONE;
				// set the correct state, so that the UART_RX_IT works correctly
				huart->gState = HAL_UART_STATE_BUSY_RX;
		}

	}
}
/* USER CODE END 0 */

int main(void)
	{

  /* USER CODE BEGIN 1 */
	//UART
	uint8_t endline=10;
	uint8_t CR=13;
	uint8_t tab=9;
	//Vonalszenzor
	uint8_t uzenetarray[5]={0,0,0,0,0};
	uint16_t pozicio_elso=1600;
	uint16_t pozicio_masodik=1200;
	uint8_t vonaltipus=EGYVONAL;
	int16_t orientacio=0;
	uint32_t szervoPWM;

  /* USER CODE END 1 */

  /* MCU Configuration----------------------------------------------------------*/

  /* Reset of all peripherals, Initializes the Flash interface and the Systick. */
  HAL_Init();

  /* Configure the system clock */
  SystemClock_Config();

  /* Initialize all configured peripherals */
  MX_GPIO_Init();
  MX_DMA_Init();
  MX_ADC1_Init();
  MX_SPI1_Init();
  MX_TIM1_Init();
  MX_TIM2_Init();
  MX_TIM8_Init();
  MX_UART4_Init();
  MX_UART5_Init();
  MX_USART1_UART_Init();
  MX_TIM6_Init();
  MX_USART2_UART_Init();
  MX_TIM4_Init();
  MX_TIM7_Init();

  /* USER CODE BEGIN 2 */
  HAL_TIMEx_PWMN_Start(&htim1, TIM_CHANNEL_2);
  HAL_TIMEx_PWMN_Start(&htim8, TIM_CHANNEL_3);
  __HAL_TIM_SET_COMPARE(&htim8, TIM_CHANNEL_3, 6932);
  //HAL_Delay(5000);*/
  //HAL_TIM_Base_Start_IT(&htim6);
  HAL_TIM_Base_Start_IT(&htim7);
  HAL_TIM_IC_Start_IT(&htim4,TIM_CHANNEL_1);
  HAL_TIM_Encoder_Start(&htim2, TIM_CHANNEL_1);

  //Vonalszenzortol uzenetek fogadasa
  //HAL_UART_Receive_DMA(&huart1,uzenetarray,3);
  HAL_UART_Receive_DMA(&huart1, uzenetarray, 5);
  HAL_UART_Receive_DMA(&huart5, &radios_uart_vevo, 1);

  /* USER CODE END 2 */

  /* Infinite loop */
  /* USER CODE BEGIN WHILE */
  //motorpulsePWM = 7252;

  while (1)
  {

	  celfigyeles(vonaltipus);
	 /* vonalobjektumtipus+=48;
	  HAL_UART_Transmit(&huart2, &vonalobjektumtipus, sizeof(uint8_t), 1000);
	  vonalobjektumtipus-=48;
	  HAL_UART_Transmit(&huart2,&endline, sizeof(uint8_t), 1000);
	  HAL_UART_Transmit(&huart2,&CR, sizeof(uint8_t), 1000);
*/
	  //UART uzenet fogadasa a vonalszenzortol
	  if(vonalszenzor_uzenetjott==true && vonalat_ignoraljuk==false) //3ms-onkent kapunk uzenetet
	  {
		  pozicio_elso = uzenetarray[0] + uzenetarray[1]*0xff;
		  pozicio_masodik = uzenetarray[2] + uzenetarray[3]*0xff;
		  vonaltipus=uzenetarray[4];
		  orientacio=pozicio_elso-pozicio_masodik;
		  allapotteres_szabalyozo(&pozicio_elso, &orientacio, &velocity, &szervoPWM);
		  __HAL_TIM_SET_COMPARE(&htim1, TIM_CHANNEL_2, szervoPWM);

		  vonal_objektum_eszleles_ugyessegi(vonaltipus, &vonalobjektumtipus);
		  vonalszenzor_uzenetjott=false;
	  }

	  /* Deadman emergency brake */
	  if(((actualmotorinput < previousmotorinput) ? actualmotorinput : previousmotorinput) < 4000)
		  stop_deadman = true;
	  else
		  stop_deadman = false;
	  if (stop_drone || stop_gyalogos || stop_radios_modulra_var || stop_hordo || stop_cel )
		  stop = true;
	  else
		  stop = false;

	  if(timestamp > 500)
	  {
		  if (!stop)
			  __HAL_TIM_SET_COMPARE(&htim8, TIM_CHANNEL_3, motorpulsePWM);
		  else if (encoderdiff > 3)
			  __HAL_TIM_SET_COMPARE(&htim8, TIM_CHANNEL_3, 4000);
		  else
			  __HAL_TIM_SET_COMPARE(&htim8, TIM_CHANNEL_3, 6932);
	  }
	  /* SHARP olvasas es kuldes */
	  if(tick)
	  {
		  HAL_ADC_Start_DMA(&hadc1, (uint32_t*) SHARPData, 3);
		  while(!SHARP_valid);
		  SHARPData2[2]=SHARPData[2];
		  SHARPData2[1]=SHARPData[1];
		  SHARPData2[0]=SHARPData[0];
		  WMAfilter(&SHARP_F,SHARPData2,SHARP_F_ARRAY,20);
		  WMAfilter(&SHARP_R,SHARPData2+1,SHARP_R_ARRAY,20);
		  WMAfilter(&SHARP_L,SHARPData2+2,SHARP_L_ARRAY,20);

		/*  sprintf(&string,"..................\r\n");
		  sprintf(&string,"%d\t%d\t%d",SHARP_L,SHARP_R, SHARP_F);
		  HAL_UART_Transmit(&huart2, &string, sizeof(string)*sizeof(uint8_t), 10000);*/
		 /* SHARP_F=SHARPData[0];
		  SHARP_R=SHARPData[1];
		  SHARP_L=SHARPData[2];*/
		  /*sprintf(&string,"..................\r\n");
		  sprintf(&string,"%d\t%d",SHARPData2[2],SHARPData2[1]);
		  HAL_UART_Transmit(&huart4, &string, sizeof(string)*sizeof(uint8_t), 10000);*/
	  //}
	  /* Sebessegmeres */
	 // if(dovelocitymeasurement) //v=[mm/s], delta t = 10ms
	  //{//valami szamitas hibas, wma filter furi.
		  state = HAL_TIM_Encoder_GetState(&htim2);
		  if(state==HAL_TIM_STATE_READY)
		  {
			  dir = __HAL_TIM_DIRECTION_STATUS(&htim2);
			  encoder1=actualencoderval*2;//valami rossza az enkoderrel, valszeg nem kapjuk meg az egyik channelt
			  encoderdiff=encoder1-encoderprev;
			  velocity=encoderdiff*10000/743;//velocity=((encoderdiff*10000)/743); //v[mm/s]
			  encoderprev=encoder1;
		  }
		  else
		  {
			  //error handling...
		  }
		  //dovelocitymeasurement=false;

		  if(oldalobjektumfigyelest_ignoraljuk==false)
		  {
			  oldal_objektum_eszeleles();
		  }

		  if(uartcsomagokszama_vonalszenzor < 10)
			  //Elkuldjuk a vonalszenzornak hogy merre menjen, es tobbszor is 10ms-enkent, hogy tuti megkapja
		  {
			  	HAL_UART_Transmit_DMA(&huart1, &merre_menjunk_ha_van_oldalfal, 1);
				uartcsomagokszama_vonalszenzor++;
//				if(utvalaszto_encoder_start!=0 && uartcsomagokszama_vonalszenzor==9 && merre_menjunk_ha_van_oldalfal==NORMAL_VONALKOVETES) //Ha ide mar akkor leptunk vissza, mikor mar a 10. NORMAL
					//vonalkoveto csomagot kuldtuk el, akkor kilepunk az uartkuldesbol
//					utvalaszto_encoder_start=0;
		  }

		  if(utvalaszto_encoder_start!=0 && encoder1-utvalaszto_encoder_start > 11150) // 150cm
		  {
			  merre_menjunk_ha_van_oldalfal=NORMAL_VONALKOVETES;
			  uartcsomagokszama_vonalszenzor=0;
			  utvalaszto_encoder_start=0;
		  }

		  if(sebszab)
		  	  sebessegszabalyozo(800);

		  tick = false;
	  }
	  if(vonalobjektumtipus==DRONE)
		  drone();
	  if(vonalobjektumtipus==GYALOGOS)
		  gyalogos();
	  if(vonalobjektumtipus==KORFORGO)
		  korforgo();
	  if(vonalobjektumtipus==HORDO)
	  {
		  hordo();
	  }
	/*  if((vonalobjektumtipus==LIBIKOKA_BALRA) || (vonalobjektumtipus==LIBIKOKA_JOBBRA))
		  libikoka();*/

	  //HORDONAL KAPCSOLJUK KI AZ OLDALOBJEKTUM ES VONALFIGYELEST
	  //TOLATASNAL kapcsoljuk ki az oldalobjektum es voalfigyelest
	  //TODO

  /* USER CODE END WHILE */

  }

}

/** System Clock Configuration
*/
void SystemClock_Config(void)
{

  RCC_OscInitTypeDef RCC_OscInitStruct;
  RCC_ClkInitTypeDef RCC_ClkInitStruct;

    /**Configure the main internal regulator output voltage
    */
  __HAL_RCC_PWR_CLK_ENABLE();

  __HAL_PWR_VOLTAGESCALING_CONFIG(PWR_REGULATOR_VOLTAGE_SCALE1);

    /**Initializes the CPU, AHB and APB busses clocks
    */
  RCC_OscInitStruct.OscillatorType = RCC_OSCILLATORTYPE_HSE;
  RCC_OscInitStruct.HSEState = RCC_HSE_ON;
  RCC_OscInitStruct.PLL.PLLState = RCC_PLL_ON;
  RCC_OscInitStruct.PLL.PLLSource = RCC_PLLSOURCE_HSE;
  RCC_OscInitStruct.PLL.PLLM = 4;
  RCC_OscInitStruct.PLL.PLLN = 180;
  RCC_OscInitStruct.PLL.PLLP = RCC_PLLP_DIV2;
  RCC_OscInitStruct.PLL.PLLQ = 2;
  RCC_OscInitStruct.PLL.PLLR = 2;
  if (HAL_RCC_OscConfig(&RCC_OscInitStruct) != HAL_OK)
  {
    Error_Handler();
  }

    /**Activate the Over-Drive mode
    */
  if (HAL_PWREx_EnableOverDrive() != HAL_OK)
  {
    Error_Handler();
  }

    /**Initializes the CPU, AHB and APB busses clocks
    */
  RCC_ClkInitStruct.ClockType = RCC_CLOCKTYPE_HCLK|RCC_CLOCKTYPE_SYSCLK
                              |RCC_CLOCKTYPE_PCLK1|RCC_CLOCKTYPE_PCLK2;
  RCC_ClkInitStruct.SYSCLKSource = RCC_SYSCLKSOURCE_PLLCLK;
  RCC_ClkInitStruct.AHBCLKDivider = RCC_SYSCLK_DIV1;
  RCC_ClkInitStruct.APB1CLKDivider = RCC_HCLK_DIV4;
  RCC_ClkInitStruct.APB2CLKDivider = RCC_HCLK_DIV2;

  if (HAL_RCC_ClockConfig(&RCC_ClkInitStruct, FLASH_LATENCY_5) != HAL_OK)
  {
    Error_Handler();
  }

    /**Configure the Systick interrupt time
    */
  HAL_SYSTICK_Config(HAL_RCC_GetHCLKFreq()/1000);

    /**Configure the Systick
    */
  HAL_SYSTICK_CLKSourceConfig(SYSTICK_CLKSOURCE_HCLK);

  /* SysTick_IRQn interrupt configuration */
  HAL_NVIC_SetPriority(SysTick_IRQn, 0, 0);
}

/* USER CODE BEGIN 4 */
uint32_t reverse_byte_order_32(uint32_t value)
{
	uint8_t lolo = (value >> 0) & 0xFF;
	uint8_t lohi = (value >> 8) & 0xFF;
	uint8_t hilo = (value >> 16) & 0xFF;
	uint8_t hihi = (value >> 24) & 0xFF;
	return (hihi << 0) | (hilo << 8) | (lohi << 16) | (lolo << 24);
}
void drone()
{
	//Q2 meresek: 480*140mm lemez feher
	//fekut 15cm
	//70cm: 1000-1010
	//60cm : 1150-1160
	//55cm : 1275-1285
	//50cm : 1405-1415
	//45cm : 1555-1565
	//Kanyar miatt mokolas: ha meglatjuk kb 80cm-re a dront, akkor meg megyunk elore 10 cm-t (+fekut)
	//Ez utan viszont pont ugy allunk, hogy nem latjuk a dront, igy elindulnank: ezert kamura varjunk 8s-t a 3 helyett

	static uint32_t encoderatstop = 0;
	static uint32_t encoderatmeasure = 0;
	static uint32_t timestampatfly = 0;
	static bool measure_distance = false;
	if ((SHARP_F > 1010/*932*/) && (!measure_distance)) //1010 jo volt egyenes szakaszon, 932 volt ivesen
	{
		//encoderatmeasure = encoder1;
		//measure_distance = true;
		stop_drone=true;
	}
	/*if (measure_distance)
	{
		if((encoder1 - encoderatmeasure) > 600) //20cm (1500), kicsit sok, eleg a ~10 (600)
		{
			stop_drone = true;
			measure_distance = false;
		}
	}*/
	if ((stop_drone) && (encoderdiff == 0))
	{
		if (encoderatstop == 0)
			encoderatstop = encoder1;

		if((SHARP_F < 650) && timestampatfly == 0)
			timestampatfly = timestamp;

		if ((SHARP_F < 650) && (timestamp - timestampatfly > 300))//800)) //3(300) masodperc, legyen 8(800)
			stop_drone = false;
	}
	if (((encoder1 - encoderatstop) > 3000) && (encoderatstop != 0)) // Feladat vege, allapotvaltas,40cm uthosszt figyelunk a dron elotti megallasi helytol
		vonalobjektumtipus=SIMA_VEZETOVONAL;

}
void gyalogos()
//Sharppal merni, megallni, ha latjuk(threshold) egyszer, majd megyunk 2s utan elengedjuk.
{
	static bool gyalogos_elottunk=false;
	static uint32_t timestamp_gyalogos=0;

	/*sprintf(&string,"...............\r\n");
	sprintf(&string,".%d",SHARP_F);
	HAL_UART_Transmit(&huart4, &string, sizeof(string)*sizeof(uint8_t), 10000);*/

	if(timestamp_gyalogos == 0)
		stop_gyalogos=true;
	if(SHARP_F > 1000)
	{
		gyalogos_elottunk=true;
	}
	if(gyalogos_elottunk && SHARP_F < 400)
	{
		gyalogos_elottunk = false;
		timestamp_gyalogos=timestamp;
		//wait 2s + indulas
	}
	if(timestamp_gyalogos != 0)
		{
			if(timestamp - timestamp_gyalogos > 100) //1s varakozas
			{
				stop_gyalogos=false;
				//gyalogos alatt innentol nem figyeljuk az oldalobjektumokat
				//allapotvisszaallitas 40cm utan: objektum sima vezetovonal, es figyeljuk az oldalobjektumokat
				//TODO

			}
		}
}

void korforgo()
{
	//JOBB kanyar kisebb atmero, 170cm -> 74,3*pi*d  39680
	//BAL kanyar nagyobb atmero, 190cm -> 44350
	static uint32_t startpozicio=0;
	static uint32_t kanyarstartpozicio=0;
	static uint8_t irany=0;

	static bool kanyarodunk = false;
	static bool elso_iteracio = false;
	/*sprintf(&string,"...............\r\n");
	sprintf(&string,"%d%\t%d",SHARP_L, SHARP_R);
	HAL_UART_Transmit(&huart4, &string, sizeof(string)*sizeof(uint8_t), 10000);*/
	if(elso_iteracio==false)
		startpozicio=encoder1;
		elso_iteracio=true;

	if (SHARP_L > 600 && irany==0)
	{
		irany=BAL;
	}
	else if (SHARP_R > 550 && irany==0)
	{
		irany = JOBB;
	}

	if(irany!=0 && kanyarodunk==false)
	{
		if(encoder1-startpozicio > 10500) //165 cm a vonalminta felismeresetol //4100) //55cm utan forditjuk a kanyart
		{
			kanyarodunk=true;
			//vonalszenzort nem figyeljuk
			vonalat_ignoraljuk=true;
			oldalobjektumfigyelest_ignoraljuk=true;
			//kanyarodunk
			if(irany==BAL)
			{
				  __HAL_TIM_SET_COMPARE(&htim1, TIM_CHANNEL_2, 5150); //5176
			}
			else //jobb
			{
				  __HAL_TIM_SET_COMPARE(&htim1, TIM_CHANNEL_2, 7000); //6684
			}
			//elmentjuk a poziciot
			kanyarstartpozicio=encoder1;
		}
	}
	if(kanyarodunk==true)
	{
		//Ha az enkoder ertek eleg nagy 340 fok, kilepunk, -> normal vezetovonal, es vonalfigyeles, kanyar false
		if(irany==BAL && (encoder1 - kanyarstartpozicio > 41500) )
		{
			kanyarodunk=false;
			vonalat_ignoraljuk=false;
			oldalobjektumfigyelest_ignoraljuk=true;
			vonalobjektumtipus=SIMA_VEZETOVONAL;
			kanyarodunk=false;
			elso_iteracio=false;
			irany=0;
			kanyarstartpozicio=0;
			startpozicio=0;

			voltmarkorforgo=true;

		}
		else if(irany==JOBB && (encoder1-kanyarstartpozicio > 39000))
		{
			kanyarodunk=false;
			oldalobjektumfigyelest_ignoraljuk=true;
			vonalat_ignoraljuk=false;
			vonalobjektumtipus=SIMA_VEZETOVONAL;
			kanyarodunk=false;
			elso_iteracio=false;
			irany=0;
			kanyarstartpozicio=0;
			startpozicio=0;

			voltmarkorforgo=true;
		}
	}

	//megvarjuk, mig latjuk a korforgot
	//elore megyunk x-et, kicspajuka kormanyt, korbemegyunk, aztan vonalkovetes
}

void hordo()
{
//Ha belepunk, gyorsitunk. 1m utan nincs vonalerzekeles, es kozepallasban megy
//Encoderrel 2m utan HA a sharpok egyike < 400 visszadjuk a kormanyzast, es lassitunk le egybol, majd pwm-et beallitjuk a normalra
	static bool kormanyzas_elvetel=false;
	static uint32_t fekezes_kezdete=0;
	static uint32_t hordostart=0;

	if(hordostart==0)
	{
		sebszab = false;
		hordostart=encoder1;
		motorpulsePWM=7800; //gyorsitas
	}
	if(encoder1-hordostart > 7430 && kormanyzas_elvetel==false) //1m
	{
		//kormanyzas elvetel
		vonalat_ignoraljuk=true;
		__HAL_TIM_SET_COMPARE(&htim1, TIM_CHANNEL_2, 6763);
		kormanyzas_elvetel=true;
	}
	if(encoder1-hordostart > 14860 && kormanyzas_elvetel==true &&/* (SHARP_L < 400 || SHARP_R < 400) &&*/ fekezes_kezdete==0)
	{
		//nem allitjuk a kormanyzaselvetelt, mert ujra belepunk az egyel ezelotti if-be, es beblokkolunk!!!
		stop_hordo=true;
		vonalat_ignoraljuk=false;
		fekezes_kezdete=timestamp;
	}
	if(fekezes_kezdete!=0 && timestamp-fekezes_kezdete>50)
	{
		stop_hordo=false;  //ez majd kell
		motorpulsePWM=7252;
		vonalobjektumtipus=SIMA_VEZETOVONAL;

		//reset, de elvileg nem kell
		kormanyzas_elvetel=false;
		fekezes_kezdete=0;
		hordostart=0;
		sebszab = true;
	}

}
void libikoka()
{
	// Elso SHARP-pal megnezzuk, hogy hol van a libikoka, majd felmegyunk ra pont annyira, hogy atbillenjen (encoderrel merjuk).
	// Ha nagyon kemenyek vagyunk, akkor egy kicsit vissza is tolatunk, hogy visszabillenjen (szinten encoder).
	// Aztan elindulunk lassan elore, megint addig, hogy visszabillenjen (encoder).
	// Ezutan visszatesszuk az allapotot SIMA_VEZETOVONAL-ba, aztan mehet minden tovabb.
	// A libikoka atbilleneset idozitovel varjuk meg. Tolataskor vonalszabalyozas ne legyen!
	/*static int32_t encoder_libikoka_start = 0;
	static uint32_t timestamp_elso_atbillentes_kezdetekor = 0;
	if((encoder_libikoka_start == 0) && (SHARP_F > 1000))// random kamu szam, ekkora ADC erteknel vesszuk eszre a libikokat
	{
		encoder_libikoka_start = encoder1;
		motorpulsePWM = 7332; // random szam, lenyeg, hogy ne repesszunk a libikokan, hanem szepen lassan menjunk fel
	}
	if((timestamp_elso_atbillentes_kezdetekor) && (encoder1 - encoder_libikoka_start > 3000)) // random kamu szam, ennyit kell menni a libikoka eszrevetele utan
		timestamp_elso_atbillentes_kezdetekor = timestamp;
	if(timestamp - timestamp_elso_atbillentes_kezdetekor > 500) // random szam, TFH 5 s alatt billen at a libikoka
	{

	}*/
	static int32_t velocity_start=0;
	static int32_t encoder_libikoka_start=0;
	static int32_t encoder_libikoka_lejto=0;
	static uint32_t libikoka_stop_kezdete=0;

	//motorpulsePWM=7500;
	if(encoder_libikoka_start==0)
	{
		velocity_start=velocity;
		encoder_libikoka_start=encoder1;
	}
	//if(encoder_libikoka_start > 1100 && encoder_libikoka_start != 0) //15cm

	if(velocity_start!=0 && velocity < (velocity_start-200))
	{
		if(encoder_libikoka_lejto==0)
			encoder_libikoka_lejto=encoder1;
	}

	if(encoder1 - encoder_libikoka_lejto > 1500 && encoder_libikoka_lejto!=0 && vonalat_ignoraljuk==false)
	{
		vonalat_ignoraljuk=true;
		oldalobjektumfigyelest_ignoraljuk=true;
	}

	if(encoder1 - encoder_libikoka_lejto > 8000 && encoder_libikoka_lejto!=0 && stop_libikoka==false)
	{
		stop_libikoka=true;
		//motorpulsePWM=7000;
		libikoka_stop_kezdete=timestamp;
		stop_drone=true;///

	}

	if(timestamp-libikoka_stop_kezdete > 300 && libikoka_stop_kezdete!=0)
	{
		stop_libikoka=false;
		stop_drone=false;
		motorpulsePWM=7252;
		vonalat_ignoraljuk=false;
		oldalobjektumfigyelest_ignoraljuk=false;

	}

	/*if(stop_libikoka==false && timestamp-libikoka_stop_kezdete > 450 && libikoka_stop_kezdete!=0)
	{
		motorpulsePWM=7252;
		stop_drone=false;
		vonalobjektumtipus=SIMA_VEZETOVONAL;
		velocity_start=0;
		encoder_libikoka_lejto=0;
		encoder_libikoka_start=0;
		libikoka_stop_kezdete=0;
	}*/

}
void WMAfilter(int32_t* filteredval, int32_t* newelement, int32_t* array, uint32_t filter_depth)
{
	*filteredval=0;
	int32_t coeffsum=0;

	for(int i=0; i<filter_depth-1; i++)
	{
		array[i]=array[i+1];
		*filteredval=*filteredval+array[i]*(i+1);
		coeffsum+=(i+1);
	}
	array[filter_depth-1]=*newelement;
	*filteredval=*filteredval+array[filter_depth-1]*(filter_depth);
	coeffsum+=(filter_depth);
	*filteredval=*filteredval/coeffsum;
}

void send16bitdecimal_to_uart(UART_HandleTypeDef* huart, uint16_t* data,uint32_t Timeout)
{
	uint16_t data2 = *data;
	uint16_t datacopy;
	uint32_t decimals;
	uint8_t txbyte;
	uint8_t issent=0;
	uint8_t space=32;
	for (int i=5; i>0; i--)
	{
		datacopy = data2;
		decimals=1;
		for (int j=i-1; j>0; j--)
		{
			datacopy=datacopy/10;
			decimals = decimals*10;
		}
		data2 -= datacopy*decimals;
		txbyte = (uint8_t) (datacopy+48);

		if(datacopy) //send spaces if zeros before the number
			issent=1;
		if(issent)
			HAL_UART_Transmit(huart, &txbyte, sizeof(txbyte), Timeout);
		else
			HAL_UART_Transmit(huart, &space, sizeof(txbyte), Timeout);
	}
}

void celfigyeles(uint8_t vonaltipus)
{
	static int32_t encoder_start=0;
	static int32_t encoder_veg=0;
	static uint8_t vonaltipus_elozo=EGYVONAL;

	if(vonaltipus==FULLVONAL)
	{
		if(encoder_start==0)
			encoder_start=encoder1;

		if(encoder1-encoder_start > 7500 && encoder1-encoder_start < 11250) //100 es 150cm kozott
		{
			if(encoder_veg==0)
			{
				encoder_veg=encoder1;
			}
			if(encoder_veg != 0 && encoder1-encoder_veg > 180 ) //(2,5cm)
			{
				stop_cel=true;
			}
		}
	}

	if(vonaltipus!=FULLVONAL)
	{
		if(encoder_start != 0 && encoder1-encoder_start > 11250)
		{
			encoder_start=0;
			encoder_veg=0;
		}
		if(encoder_veg != 0 && encoder1-encoder_veg > 700) //10cm
			encoder_start=0;
			encoder_veg=0;
	}

}

void vonal_objektum_eszleles_ugyessegi (uint8_t vonaltipus, uint8_t* objektumtipus)
{
	static bool vonalobjektum_megfigyeles = false;
	static uint8_t elozo_vonaltipus = EGYVONAL;
	static uint32_t encodervalelso = 0;
	static uint8_t nemvonalak=0;
	static uint8_t egyvonalak=0;
	static uint8_t ketvonalak=0;
	static uint8_t haromvonalak=0;

	if(vonalobjektum_megfigyeles==false && (vonaltipus == KETVONAL || vonaltipus == HAROMVONAL || vonaltipus == NINCSVONAL))
	{
		vonalobjektum_megfigyeles=true;
		encodervalelso = actualencoderval;
	}
	if(vonalobjektum_megfigyeles==true)
	{
		//223 encoder ertek = 3cm
		if(elozo_vonaltipus != vonaltipus)//Uj vonaltipusra erkeztunk
		{

			if ((actualencoderval-encodervalelso)> 223) //nagyobb a vonalminta, mint 3cm, vagy csak kamu?
			{
				if(elozo_vonaltipus==EGYVONAL)
					egyvonalak++;
				else if(elozo_vonaltipus==KETVONAL)
					ketvonalak++;
				else if(elozo_vonaltipus==HAROMVONAL)
					haromvonalak++;
				else
					nemvonalak++;

				//Vegen vagyunk mar az objektumnak???
				//Milyen objektumnak?
				if(((actualencoderval-encodervalelso)> 1485) && elozo_vonaltipus==HAROMVONAL) //Hosszu 20cm 3-vonal: dron
				{
					*objektumtipus=DRONE;
				}
				//if((elozo_vonaltipus==HAROMVONAL) && haromvonalak > 1 && egyvonalak > 0)
				if((elozo_vonaltipus==HAROMVONAL) && haromvonalak > 3 && egyvonalak > 2)
				{
					*objektumtipus=GYALOGOS;
				}
				if((elozo_vonaltipus==KETVONAL) && ketvonalak > 2 && egyvonalak > 1)
				{
					*objektumtipus=HORDO;
				}
				//if((elozo_vonaltipus==NINCSVONAL) && nemvonalak > 1 && egyvonalak > 0)
				if((elozo_vonaltipus==NINCSVONAL) && nemvonalak > 2 && egyvonalak > 1)
				{
					*objektumtipus=KORFORGO;
				}
				encodervalelso=actualencoderval;

			}
		}

		if(vonaltipus==EGYVONAL)
			{
				if((actualencoderval-encodervalelso)> 1115)
				{
					//Ha 15 cm ota egyvonal van, akkor vege az objektumfigyelesnek
					vonalobjektum_megfigyeles=false;
					nemvonalak=0;
					egyvonalak=0;
					ketvonalak=0;
					haromvonalak=0;
				}
			}

		elozo_vonaltipus=vonaltipus;
	}
// ha semmi sem igaz, akkor nem allitjuk az sima vezetovonalra a vonaltipust, az az akadalykezelo fuggveny dolga
}
void oldal_objektum_eszeleles()
//Utanfuto: 2 fal 50cm, majd egy fal, es ujra 2 fal
//Kapu: 2 fal 60cm
//bordasfal
//sima fal
{
	static bool oldalobjektummegfigyeles = false;
	static bool parkolosejtes=false;
	static uint8_t oldal=0;
	static uint8_t elozo_oldal=0; //
	static uint32_t encoder_elso=0;
	static uint32_t encoder_utolso=0;
	//static int32_t oldaltavolsag_bordahoz=0;
	static bool bordas=false;
	static bool elsore_nem_latunk_semmit=true;
	static bool varakozas_az_oldalobjektum_vegere=false;
	static int32_t SHARPmax=0;
	static int32_t SHARPmin=4096;
	static uint32_t parkolosejtesencoder=0;

	if(SHARP_L > 600 && SHARP_R > 600)
	{
		oldal=MINDKET_OLDAL;
	}
	else if(SHARP_L > 600)
	{
		oldal=BAL;
	}
	else if(SHARP_R > 600)
	{
		oldal=JOBB;
	}
	else
		oldal=0;

	if(oldalobjektummegfigyeles == false && oldal!=0)
	{
		oldalobjektummegfigyeles=true;
		encoder_elso=encoder1;
	}
	if(varakozas_az_oldalobjektum_vegere==true)
	{
		//vajon parkolo volt amibol kileptunk?
		if(parkolosejtes && oldal!=0)
		{
			if(encoder1-parkolosejtesencoder > 743) //ha 10cm ota latunk oldalvonalat, akkor parkolo lesz
			{
				if(oldal==BAL)
				{
					vonalobjektumtipus=PARKOLO_JOBBRA;
				}
				else if(oldal==JOBB)
				{
					vonalobjektumtipus=PARKOLO_BALRA;
				}
				parkolosejtes=false;
			}
		}

		//ha mar 5cm ota nem latunk semmit, akkor kilepunk. ide akkor lepunk, ha mar fixen detektaltuk az egyik allapotot
		if(oldal==0)
		{
			if(elsore_nem_latunk_semmit==true)
			{
				elsore_nem_latunk_semmit=false;
				encoder_utolso=encoder1;
				if(parkolosejtes)
				{
					parkolosejtes=false;
					//Kapu, semmit sem csinalunk
				}
			}
			if(encoder1-encoder_utolso > 446 && elsore_nem_latunk_semmit==false) //6cm utan semmit se latnuk, akkor exit
			{
				//kilepes, reset
				elsore_nem_latunk_semmit=true;
				oldalobjektummegfigyeles=false;
				varakozas_az_oldalobjektum_vegere=false;
				bordas=false;
				SHARPmax=0;
				SHARPmin=4096;
			}
		}
	}
	if(oldalobjektummegfigyeles==true && varakozas_az_oldalobjektum_vegere==false)
	{

		if(elozo_oldal==oldal && (oldal==JOBB || oldal==BAL) && bordas==false && encoder1-encoder_elso > 745 && encoder1-encoder_elso < 3725) //10cm utan merunk de csak 50cm-ig
		{
			if(oldal==JOBB)
			{
				if(SHARPmax < SHARP_R)
				{
					SHARPmax=SHARP_R;
				}
				if(SHARPmin > SHARP_R)
				{
					SHARPmin=SHARP_R;
				}
			}
			else if(oldal==BAL)
			{
				if(SHARPmax < SHARP_L)
				{
					SHARPmax=SHARP_L;
				}
				if(SHARPmin > SHARP_L)
				{
					SHARPmin=SHARP_L;
				}
			}
			if(SHARPmax-SHARPmin > 140)
			{
				bordas=true;
				SHARPmax=0;
				SHARPmin=4096;
				//oldaltavolsag_bordahoz=0;
			}

			/*if(encoder1-encoder_elso > 745) //10cm utab merunk, hogy milyen messze van a fal (bordashoz kell)
			{
				if(oldal==JOBB && oldaltavolsag_bordahoz==0)
					oldaltavolsag_bordahoz=SHARP_R;
				else if (oldal==BAL && oldaltavolsag_bordahoz==0)
					oldaltavolsag_bordahoz=SHARP_L;
			}
			if(oldal==JOBB && oldaltavolsag_bordahoz-SHARP_R > 110)
			{
				bordas=true;
				oldaltavolsag_bordahoz=0;
			}
			if(oldal==BAL && oldaltavolsag_bordahoz-SHARP_L > 110)
			{
				bordas=true;
				oldaltavolsag_bordahoz=0;
			}*/
		}

		if(oldal==0)
		{
			if(elsore_nem_latunk_semmit==true)
			{
				elsore_nem_latunk_semmit=false;
				encoder_utolso=encoder1;
			}
			if(encoder1-encoder_utolso > 446 && elsore_nem_latunk_semmit==false) //6cm utan semmit se latnuk, akkor exit
			{
				//kilepes, reset
				elsore_nem_latunk_semmit=true;
				oldalobjektummegfigyeles=false;
				bordas=false;
				SHARPmax=0;
				SHARPmin=4096;
			}
		}
		if(oldal!=0)
			elsore_nem_latunk_semmit=true;

		if(elozo_oldal!=oldal)
		{

			if(encoder1-encoder_elso > 2230) //30cm utan vesszuk figyelembe a targyat
			{
				if(bordas && elozo_oldal==JOBB)
				{
					vonalobjektumtipus=TELEPHELY_BALRA;
					uartcsomagokszama_vonalszenzor=0;
					utvalaszto_encoder_start=encoder1; //150 cm utan kuldunk egy uzenetet, hogy alljon vissza normal allapotra
					merre_menjunk_ha_van_oldalfal=JOBB;//BAL; gany
				}
				if(bordas && elozo_oldal==BAL)
				{
					vonalobjektumtipus=TELEPHELY_JOBBRA;
					uartcsomagokszama_vonalszenzor=0;
					utvalaszto_encoder_start=encoder1; //150 cm utan kuldunk egy uzenetet, hogy alljon vissza normal allapotra
					merre_menjunk_ha_van_oldalfal=BAL;//JOBB; gany
				}
				if(bordas==false && elozo_oldal==JOBB)
				{
					vonalobjektumtipus=LIBIKOKA_BALRA;
					uartcsomagokszama_vonalszenzor=0;
					utvalaszto_encoder_start=encoder1; //150 cm utan kuldunk egy uzenetet, hogy alljon vissza normal allapotra
					merre_menjunk_ha_van_oldalfal=BAL; //JOBB;gany ///!!!!!
				}
				if(bordas==false && elozo_oldal==BAL)
				{
					vonalobjektumtipus=LIBIKOKA_JOBBRA;
					uartcsomagokszama_vonalszenzor=0;
					utvalaszto_encoder_start=encoder1; //150 cm utan kuldunk egy uzenetet, hogy alljon vissza normal allapotra
					merre_menjunk_ha_van_oldalfal=JOBB; //BAL;gany ////!!!!!!
				}

				if(elozo_oldal==MINDKET_OLDAL && (oldal==BAL || oldal==JOBB))
				{
					parkolosejtes=true;
					parkolosejtesencoder=encoder1;
				}
				else
				{
					;
					//KAPU, ekkor nincs semmi, bar ilyen valszeg sose lesz, mert a kapu egyik oldala bezajol.
					//erre valo a parkolosejtes, kesobb (feljebb) vizsgaljuk, hogy kajak van oldalfal, vagy csak egy par cm maradt az egyik kapuoldalbol
				}
				//oldaltavolsag_bordahoz=0;
				varakozas_az_oldalobjektum_vegere=true;
				//oldalobjektummegfigyeles=false;
				bordas=false;
				SHARPmax=0;
				SHARPmin=4096;
			}
		}

		elozo_oldal=oldal;
	}
}

void allapotteres_szabalyozo(uint16_t* pozicio, int16_t* orientacio, int32_t* sebesseg, uint32_t* PWMeredmeny)
{
	float arctaneredmeny;
	arctaneredmeny=atan_lut[*orientacio+2300];
	*PWMeredmeny = (uint32_t) (-251.1077*(2*((float)*pozicio)-3300)/(1082.1041*(0.00038889*(0.0)+1.0556)*(0.00038889*(0.0)+1.0556))-(-0.855-0.00063*(0.0))*arctaneredmeny/((0.00038889*(0.0)+1.0556)*(0.00038889*(0.0)+1.0556))+5930.0);
	if(*PWMeredmeny > 7250)
		*PWMeredmeny=7250;
	else if(*PWMeredmeny < 4610)
		*PWMeredmeny=4610;

	//*PWMeredmeny = (uint32_t) ( -3.1667*((float)*pozicio)/((0.00038889*((float)*sebesseg)+1.0556)*(0.00038889*((float)*sebesseg)+1.0556))+(-0.855-0.00063*((float)*sebesseg))*arctaneredmeny/((0.00038889*((float)*sebesseg)+1.0556)*(0.00038889*((float)*sebesseg)+1.0556))+6763.5);
}
void sebessegszabalyozo(int32_t mmpersec)
{

	// Belso valtozok
	int32_t alapjel = mmpersec;
	static int32_t elozo_alapjel = 0;
	static float beavatkozo_jel = 0;
	static float elozo_beavatkozo_jel = 0;
	static float pozitiv_visszacsatolas = 0;
	float FOXBORO_bemeno_jel = 0;
	if(alapjel-elozo_alapjel > 1)
		alapjel = elozo_alapjel+1;
	// Szabalyozas
	// Szabalyozasi algoritmus
	pozitiv_visszacsatolas = 0.99288*pozitiv_visszacsatolas+0.0071168*beavatkozo_jel;
	FOXBORO_bemeno_jel = 0.9029*(mmpersec-velocity)+pozitiv_visszacsatolas;
	// Beavatkozo szerv telites kezelese
	if(FOXBORO_bemeno_jel > 1500)
		beavatkozo_jel = 1500;
	else if(FOXBORO_bemeno_jel < -4000)
		beavatkozo_jel = -4000;
	else
		beavatkozo_jel = FOXBORO_bemeno_jel;
	// Inverz statikus nemlinearitas
	if(beavatkozo_jel > 0)
	{
		if((0 < beavatkozo_jel) && (beavatkozo_jel <= 112.0907))
			beavatkozo_jel = 200+0.89213*beavatkozo_jel;
		else if((112.0907 < beavatkozo_jel) && (beavatkozo_jel <= 350.2835))
			beavatkozo_jel = 300+0.41983*(beavatkozo_jel-112.0907);
		else if((350.2835 < beavatkozo_jel) && (beavatkozo_jel <= 560.4536))
			beavatkozo_jel = 400+0.47581*(beavatkozo_jel-350.2835);
		else if((560.4536 < beavatkozo_jel) && (beavatkozo_jel <= 756.6123))
			beavatkozo_jel = 500+0.50979*(beavatkozo_jel-560.4536);
		else if((756.6123 < beavatkozo_jel) && (beavatkozo_jel <= 910.737))
			beavatkozo_jel = 600+0.64883*(beavatkozo_jel-756.6123);
	}
	// Beavatkozo jel kiadasa
	motorpulsePWM = (uint32_t) (beavatkozo_jel+6932);
	// Integratorok feltoltese
	elozo_alapjel = alapjel;
	elozo_beavatkozo_jel = beavatkozo_jel;
}

/* USER CODE END 4 */

void Error_Handler(void)
{
  while(1)
  {
  }
}

/************************ (C) COPYRIGHT STMicroelectronics *****END OF FILE****/
